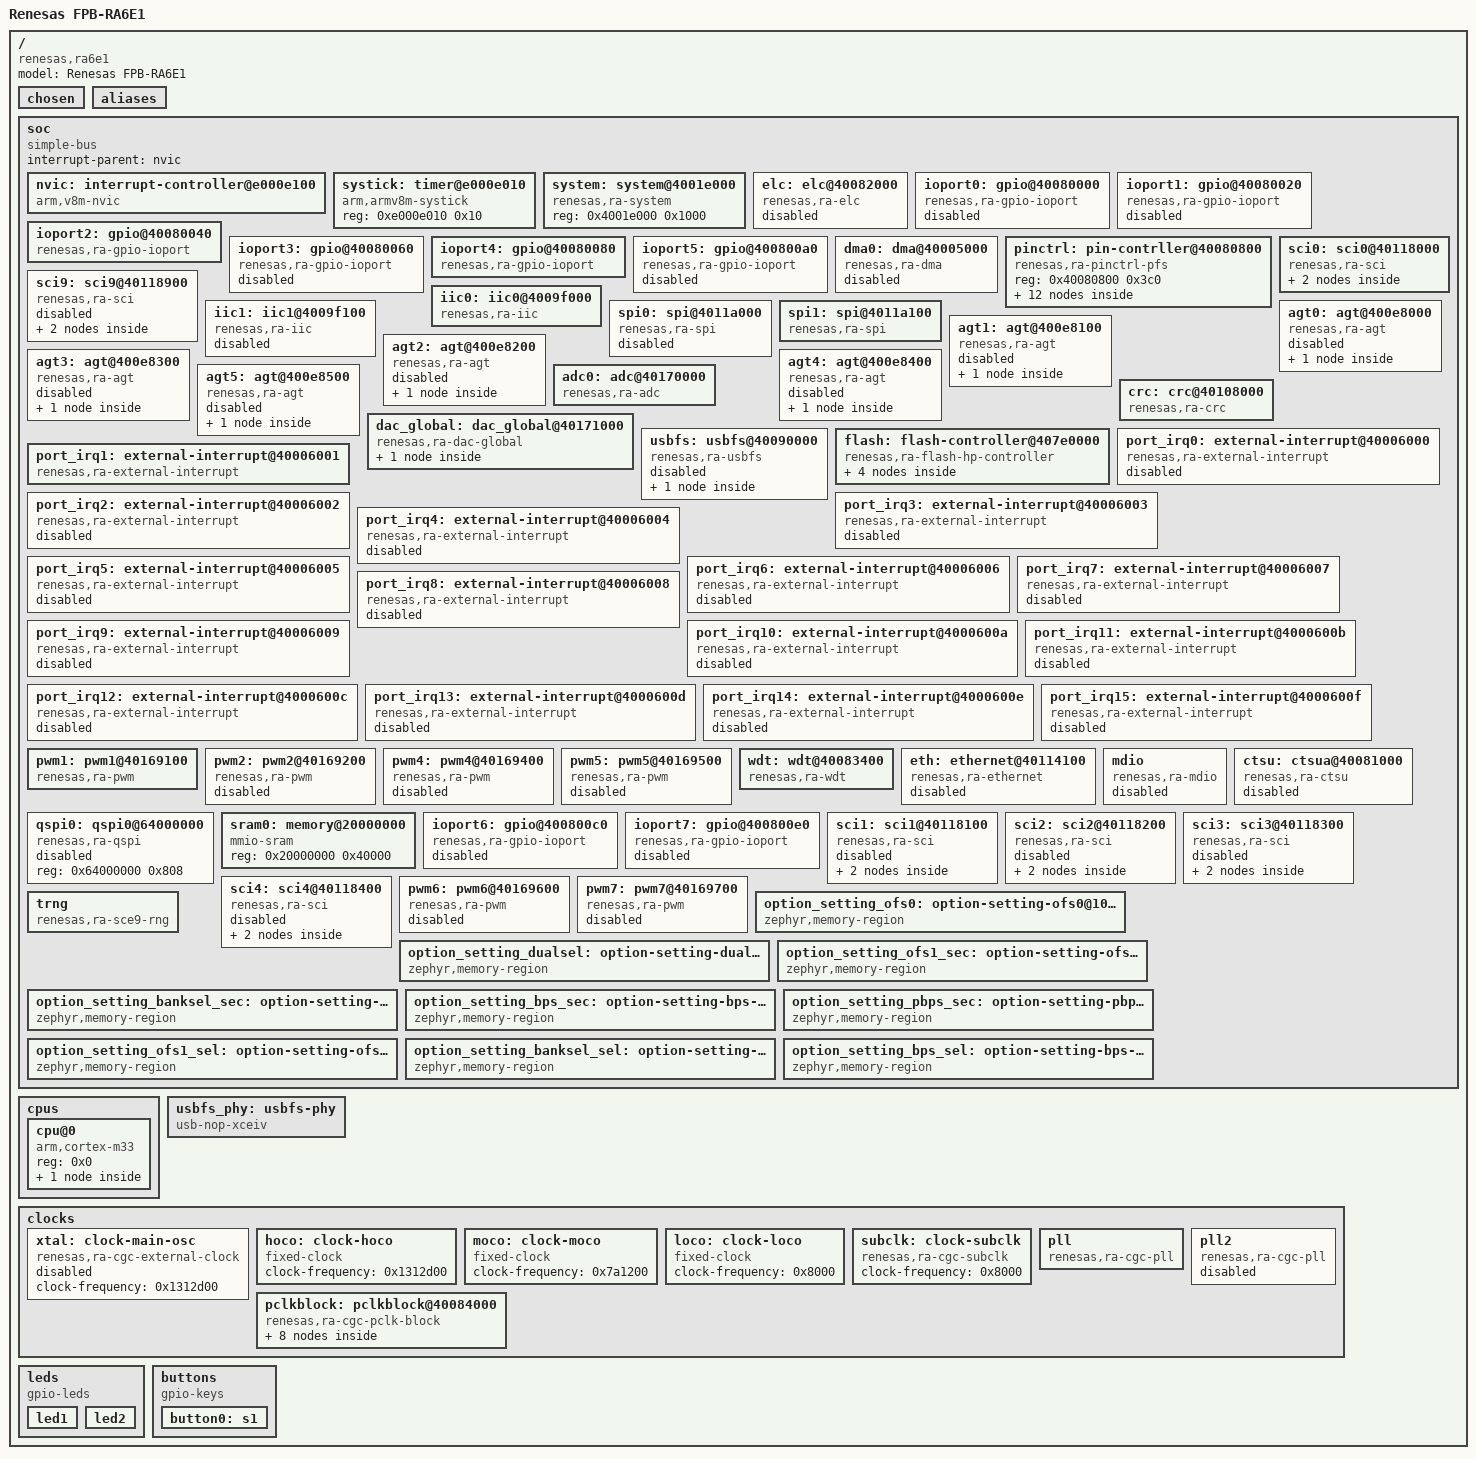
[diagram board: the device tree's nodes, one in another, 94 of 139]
/dts-v1/;

/* node '/' defined in zephyr/dts/common/skeleton.dtsi:9 */
/ {
	#address-cells = < 0x1 >;     /* in zephyr/dts/common/skeleton.dtsi:10 */
	#size-cells = < 0x1 >;        /* in zephyr/dts/common/skeleton.dtsi:11 */
	model = "Renesas FPB-RA6E1";  /* in zephyr/boards/renesas/fpb_ra6e1/fpb_ra6e1.dts:16 */
	compatible = "renesas,ra6e1",
	             "renesas,ra";    /* in zephyr/boards/renesas/fpb_ra6e1/fpb_ra6e1.dts:17 */

	/* node '/chosen' defined in zephyr/dts/common/skeleton.dtsi:13 */
	chosen {
		zephyr,sram = &sram0;              /* in zephyr/boards/renesas/fpb_ra6e1/fpb_ra6e1.dts:20 */
		zephyr,flash-controller = &flash1; /* in zephyr/boards/renesas/fpb_ra6e1/fpb_ra6e1.dts:21 */
		zephyr,flash = &flash0;            /* in zephyr/boards/renesas/fpb_ra6e1/fpb_ra6e1.dts:22 */
		zephyr,console = &uart0;           /* in zephyr/boards/renesas/fpb_ra6e1/fpb_ra6e1.dts:23 */
		zephyr,shell-uart = &uart0;        /* in zephyr/boards/renesas/fpb_ra6e1/fpb_ra6e1.dts:24 */
		zephyr,entropy = &trng;            /* in zephyr/boards/renesas/fpb_ra6e1/fpb_ra6e1.dts:25 */
		zephyr,crc = &crc;                 /* in zephyr/boards/renesas/fpb_ra6e1/fpb_ra6e1.dts:26 */
	};

	/* node '/aliases' defined in zephyr/dts/common/skeleton.dtsi:15 */
	aliases {
		led0 = &led1;     /* in zephyr/boards/renesas/fpb_ra6e1/fpb_ra6e1.dts:54 */
		sw0 = &button0;   /* in zephyr/boards/renesas/fpb_ra6e1/fpb_ra6e1.dts:55 */
		watchdog0 = &wdt; /* in zephyr/boards/renesas/fpb_ra6e1/fpb_ra6e1.dts:56 */
	};

	/* node '/soc' defined in zephyr/dts/arm/armv8-m.dtsi:6 */
	soc {
		#address-cells = < 0x1 >;     /* in zephyr/dts/arm/armv8-m.dtsi:7 */
		#size-cells = < 0x1 >;        /* in zephyr/dts/arm/armv8-m.dtsi:8 */
		compatible = "simple-bus";    /* in zephyr/dts/arm/armv8-m.dtsi:9 */
		ranges;                       /* in zephyr/dts/arm/armv8-m.dtsi:11 */
		interrupt-parent = < &nvic >; /* in zephyr/dts/arm/renesas/ra/ra6/ra6-cm33-common.dtsi:34 */

		/* node '/soc/interrupt-controller@e000e100' defined in zephyr/dts/arm/armv8-m.dtsi:13 */
		nvic: interrupt-controller@e000e100 {
			#address-cells = < 0x1 >;            /* in zephyr/dts/arm/armv8-m.dtsi:14 */
			compatible = "arm,v8m-nvic";         /* in zephyr/dts/arm/armv8-m.dtsi:15 */
			reg = < 0xe000e100 0xc00 >;          /* in zephyr/dts/arm/armv8-m.dtsi:16 */
			interrupt-controller;                /* in zephyr/dts/arm/armv8-m.dtsi:17 */
			#interrupt-cells = < 0x2 >;          /* in zephyr/dts/arm/armv8-m.dtsi:18 */
			arm,num-irq-priority-bits = < 0x4 >; /* in zephyr/dts/arm/renesas/ra/ra6/ra6-cm33-common.dtsi:603 */
			phandle = < 0x1 >;                   /* in zephyr/dts/arm/renesas/ra/ra6/ra6-cm33-common.dtsi:34 */
		};

		/* node '/soc/timer@e000e010' defined in zephyr/dts/arm/armv8-m.dtsi:21 */
		systick: timer@e000e010 {
			compatible = "arm,armv8m-systick"; /* in zephyr/dts/arm/armv8-m.dtsi:22 */
			reg = < 0xe000e010 0x10 >;         /* in zephyr/dts/arm/armv8-m.dtsi:23 */
		};

		/* node '/soc/system@4001e000' defined in zephyr/dts/arm/renesas/ra/ra6/ra6-cm33-common.dtsi:36 */
		system: system@4001e000 {
			compatible = "renesas,ra-system"; /* in zephyr/dts/arm/renesas/ra/ra6/ra6-cm33-common.dtsi:37 */
			reg = < 0x4001e000 0x1000 >;      /* in zephyr/dts/arm/renesas/ra/ra6/ra6-cm33-common.dtsi:38 */
			status = "okay";                  /* in zephyr/dts/arm/renesas/ra/ra6/ra6-cm33-common.dtsi:39 */
		};

		/* node '/soc/elc@40082000' defined in zephyr/dts/arm/renesas/ra/ra6/ra6-cm33-common.dtsi:42 */
		elc: elc@40082000 {
			compatible = "renesas,ra-elc"; /* in zephyr/dts/arm/renesas/ra/ra6/ra6-cm33-common.dtsi:43 */
			reg = < 0x40082000 0x70 >;     /* in zephyr/dts/arm/renesas/ra/ra6/ra6-cm33-common.dtsi:44 */
			#renesas-elc-cells = < 0x2 >;  /* in zephyr/dts/arm/renesas/ra/ra6/ra6-cm33-common.dtsi:45 */
			clocks = < &pclkb 0x2 0xe >;   /* in zephyr/dts/arm/renesas/ra/ra6/ra6-cm33-common.dtsi:46 */
			status = "disabled";           /* in zephyr/dts/arm/renesas/ra/ra6/ra6-cm33-common.dtsi:47 */
		};

		/* node '/soc/gpio@40080000' defined in zephyr/dts/arm/renesas/ra/ra6/ra6-cm33-common.dtsi:50 */
		ioport0: gpio@40080000 {
			compatible = "renesas,ra-gpio-ioport";                                                                       /* in zephyr/dts/arm/renesas/ra/ra6/ra6-cm33-common.dtsi:51 */
			reg = < 0x40080000 0x20 >;                                                                                   /* in zephyr/dts/arm/renesas/ra/ra6/ra6-cm33-common.dtsi:52 */
			port = < 0x0 >;                                                                                              /* in zephyr/dts/arm/renesas/ra/ra6/ra6-cm33-common.dtsi:53 */
			gpio-controller;                                                                                             /* in zephyr/dts/arm/renesas/ra/ra6/ra6-cm33-common.dtsi:54 */
			#gpio-cells = < 0x2 >;                                                                                       /* in zephyr/dts/arm/renesas/ra/ra6/ra6-cm33-common.dtsi:55 */
			ngpios = < 0x10 >;                                                                                           /* in zephyr/dts/arm/renesas/ra/ra6/ra6-cm33-common.dtsi:56 */
			status = "disabled";                                                                                         /* in zephyr/dts/arm/renesas/ra/ra6/ra6-cm33-common.dtsi:57 */
			port-irqs = < &port_irq6 &port_irq7 &port_irq8 &port_irq9 &port_irq10 &port_irq11 &port_irq12 &port_irq13 >; /* in zephyr/dts/arm/renesas/ra/ra6/r7fa6e10x.dtsi:353 */
			port-irq-names = "port-irq6",
			                 "port-irq7",
			                 "port-irq8",
			                 "port-irq9",
			                 "port-irq10",
			                 "port-irq11",
			                 "port-irq12",
			                 "port-irq13";                                                                               /* in zephyr/dts/arm/renesas/ra/ra6/r7fa6e10x.dtsi:356 */
			port-irq6-pins = < 0x0 >;                                                                                    /* in zephyr/dts/arm/renesas/ra/ra6/r7fa6e10x.dtsi:364 */
			port-irq7-pins = < 0x1 >;                                                                                    /* in zephyr/dts/arm/renesas/ra/ra6/r7fa6e10x.dtsi:365 */
			port-irq8-pins = < 0x2 >;                                                                                    /* in zephyr/dts/arm/renesas/ra/ra6/r7fa6e10x.dtsi:366 */
			port-irq9-pins = < 0x4 >;                                                                                    /* in zephyr/dts/arm/renesas/ra/ra6/r7fa6e10x.dtsi:367 */
			port-irq10-pins = < 0x5 >;                                                                                   /* in zephyr/dts/arm/renesas/ra/ra6/r7fa6e10x.dtsi:368 */
			port-irq11-pins = < 0x6 >;                                                                                   /* in zephyr/dts/arm/renesas/ra/ra6/r7fa6e10x.dtsi:369 */
			port-irq12-pins = < 0x8 >;                                                                                   /* in zephyr/dts/arm/renesas/ra/ra6/r7fa6e10x.dtsi:370 */
			port-irq13-pins = < 0xf >;                                                                                   /* in zephyr/dts/arm/renesas/ra/ra6/r7fa6e10x.dtsi:371 */
		};

		/* node '/soc/gpio@40080020' defined in zephyr/dts/arm/renesas/ra/ra6/ra6-cm33-common.dtsi:60 */
		ioport1: gpio@40080020 {
			compatible = "renesas,ra-gpio-ioport";                                  /* in zephyr/dts/arm/renesas/ra/ra6/ra6-cm33-common.dtsi:61 */
			reg = < 0x40080020 0x20 >;                                              /* in zephyr/dts/arm/renesas/ra/ra6/ra6-cm33-common.dtsi:62 */
			port = < 0x1 >;                                                         /* in zephyr/dts/arm/renesas/ra/ra6/ra6-cm33-common.dtsi:63 */
			gpio-controller;                                                        /* in zephyr/dts/arm/renesas/ra/ra6/ra6-cm33-common.dtsi:64 */
			#gpio-cells = < 0x2 >;                                                  /* in zephyr/dts/arm/renesas/ra/ra6/ra6-cm33-common.dtsi:65 */
			ngpios = < 0x10 >;                                                      /* in zephyr/dts/arm/renesas/ra/ra6/ra6-cm33-common.dtsi:66 */
			status = "disabled";                                                    /* in zephyr/dts/arm/renesas/ra/ra6/ra6-cm33-common.dtsi:67 */
			port-irqs = < &port_irq0 &port_irq1 &port_irq2 &port_irq3 &port_irq4 >; /* in zephyr/dts/arm/renesas/ra/ra6/r7fa6e10x.dtsi:375 */
			port-irq-names = "port-irq0",
			                 "port-irq1",
			                 "port-irq2",
			                 "port-irq3",
			                 "port-irq4";                                           /* in zephyr/dts/arm/renesas/ra/ra6/r7fa6e10x.dtsi:377 */
			port-irq0-pins = < 0x5 >;                                               /* in zephyr/dts/arm/renesas/ra/ra6/r7fa6e10x.dtsi:382 */
			port-irq1-pins = < 0x1 0x4 >;                                           /* in zephyr/dts/arm/renesas/ra/ra6/r7fa6e10x.dtsi:383 */
			port-irq2-pins = < 0x0 >;                                               /* in zephyr/dts/arm/renesas/ra/ra6/r7fa6e10x.dtsi:384 */
			port-irq3-pins = < 0xa >;                                               /* in zephyr/dts/arm/renesas/ra/ra6/r7fa6e10x.dtsi:385 */
			port-irq4-pins = < 0xb >;                                               /* in zephyr/dts/arm/renesas/ra/ra6/r7fa6e10x.dtsi:386 */
		};

		/* node '/soc/gpio@40080040' defined in zephyr/dts/arm/renesas/ra/ra6/ra6-cm33-common.dtsi:70 */
		ioport2: gpio@40080040 {
			compatible = "renesas,ra-gpio-ioport";                       /* in zephyr/dts/arm/renesas/ra/ra6/ra6-cm33-common.dtsi:71 */
			reg = < 0x40080040 0x20 >;                                   /* in zephyr/dts/arm/renesas/ra/ra6/ra6-cm33-common.dtsi:72 */
			port = < 0x2 >;                                              /* in zephyr/dts/arm/renesas/ra/ra6/ra6-cm33-common.dtsi:73 */
			gpio-controller;                                             /* in zephyr/dts/arm/renesas/ra/ra6/ra6-cm33-common.dtsi:74 */
			#gpio-cells = < 0x2 >;                                       /* in zephyr/dts/arm/renesas/ra/ra6/ra6-cm33-common.dtsi:75 */
			ngpios = < 0x10 >;                                           /* in zephyr/dts/arm/renesas/ra/ra6/ra6-cm33-common.dtsi:76 */
			port-irqs = < &port_irq0 &port_irq1 &port_irq2 &port_irq3 >; /* in zephyr/dts/arm/renesas/ra/ra6/r7fa6e10x.dtsi:390 */
			port-irq-names = "port-irq0",
			                 "port-irq1",
			                 "port-irq2",
			                 "port-irq3";                                /* in zephyr/dts/arm/renesas/ra/ra6/r7fa6e10x.dtsi:392 */
			port-irq0-pins = < 0x6 >;                                    /* in zephyr/dts/arm/renesas/ra/ra6/r7fa6e10x.dtsi:396 */
			port-irq1-pins = < 0x5 >;                                    /* in zephyr/dts/arm/renesas/ra/ra6/r7fa6e10x.dtsi:397 */
			port-irq2-pins = < 0xd >;                                    /* in zephyr/dts/arm/renesas/ra/ra6/r7fa6e10x.dtsi:398 */
			port-irq3-pins = < 0xc >;                                    /* in zephyr/dts/arm/renesas/ra/ra6/r7fa6e10x.dtsi:399 */
			status = "okay";                                             /* in zephyr/boards/renesas/fpb_ra6e1/fpb_ra6e1.dts:89 */
			phandle = < 0x22 >;                                          /* in zephyr/boards/renesas/fpb_ra6e1/fpb_ra6e1.dts:47 */
		};

		/* node '/soc/gpio@40080060' defined in zephyr/dts/arm/renesas/ra/ra6/ra6-cm33-common.dtsi:80 */
		ioport3: gpio@40080060 {
			compatible = "renesas,ra-gpio-ioport";                       /* in zephyr/dts/arm/renesas/ra/ra6/ra6-cm33-common.dtsi:81 */
			reg = < 0x40080060 0x20 >;                                   /* in zephyr/dts/arm/renesas/ra/ra6/ra6-cm33-common.dtsi:82 */
			port = < 0x3 >;                                              /* in zephyr/dts/arm/renesas/ra/ra6/ra6-cm33-common.dtsi:83 */
			gpio-controller;                                             /* in zephyr/dts/arm/renesas/ra/ra6/ra6-cm33-common.dtsi:84 */
			#gpio-cells = < 0x2 >;                                       /* in zephyr/dts/arm/renesas/ra/ra6/ra6-cm33-common.dtsi:85 */
			ngpios = < 0x10 >;                                           /* in zephyr/dts/arm/renesas/ra/ra6/ra6-cm33-common.dtsi:86 */
			status = "disabled";                                         /* in zephyr/dts/arm/renesas/ra/ra6/ra6-cm33-common.dtsi:87 */
			port-irqs = < &port_irq5 &port_irq6 &port_irq8 &port_irq9 >; /* in zephyr/dts/arm/renesas/ra/ra6/r7fa6e10x.dtsi:403 */
			port-irq-names = "port-irq5",
			                 "port-irq6",
			                 "port-irq8",
			                 "port-irq9";                                /* in zephyr/dts/arm/renesas/ra/ra6/r7fa6e10x.dtsi:405 */
			port-irq5-pins = < 0x2 >;                                    /* in zephyr/dts/arm/renesas/ra/ra6/r7fa6e10x.dtsi:409 */
			port-irq6-pins = < 0x1 >;                                    /* in zephyr/dts/arm/renesas/ra/ra6/r7fa6e10x.dtsi:410 */
			port-irq8-pins = < 0x5 >;                                    /* in zephyr/dts/arm/renesas/ra/ra6/r7fa6e10x.dtsi:411 */
			port-irq9-pins = < 0x4 >;                                    /* in zephyr/dts/arm/renesas/ra/ra6/r7fa6e10x.dtsi:412 */
		};

		/* node '/soc/gpio@40080080' defined in zephyr/dts/arm/renesas/ra/ra6/ra6-cm33-common.dtsi:90 */
		ioport4: gpio@40080080 {
			compatible = "renesas,ra-gpio-ioport";                                                                 /* in zephyr/dts/arm/renesas/ra/ra6/ra6-cm33-common.dtsi:91 */
			reg = < 0x40080080 0x20 >;                                                                             /* in zephyr/dts/arm/renesas/ra/ra6/ra6-cm33-common.dtsi:92 */
			port = < 0x4 >;                                                                                        /* in zephyr/dts/arm/renesas/ra/ra6/ra6-cm33-common.dtsi:93 */
			gpio-controller;                                                                                       /* in zephyr/dts/arm/renesas/ra/ra6/ra6-cm33-common.dtsi:94 */
			#gpio-cells = < 0x2 >;                                                                                 /* in zephyr/dts/arm/renesas/ra/ra6/ra6-cm33-common.dtsi:95 */
			ngpios = < 0x10 >;                                                                                     /* in zephyr/dts/arm/renesas/ra/ra6/ra6-cm33-common.dtsi:96 */
			vbatts-pins = < 0x2 0x3 0x4 >;                                                                         /* in zephyr/dts/arm/renesas/ra/ra6/ra6-cm33-common.dtsi:97 */
			port-irqs = < &port_irq0 &port_irq4 &port_irq5 &port_irq6 &port_irq7 &port_irq8 &port_irq9 &port_irq14
			              &port_irq15 >;                                                                           /* in zephyr/dts/arm/renesas/ra/ra6/r7fa6e10x.dtsi:416 */
			port-irq-names = "port-irq0",
			                 "port-irq4",
			                 "port-irq5",
			                 "port-irq6",
			                 "port-irq7",
			                 "port-irq8",
			                 "port-irq9",
			                 "port-irq14",
			                 "port-irq15";                                                                         /* in zephyr/dts/arm/renesas/ra/ra6/r7fa6e10x.dtsi:419 */
			port-irq0-pins = < 0x0 >;                                                                              /* in zephyr/dts/arm/renesas/ra/ra6/r7fa6e10x.dtsi:428 */
			port-irq4-pins = < 0x2 0xb >;                                                                          /* in zephyr/dts/arm/renesas/ra/ra6/r7fa6e10x.dtsi:429 */
			port-irq5-pins = < 0x1 0xa >;                                                                          /* in zephyr/dts/arm/renesas/ra/ra6/r7fa6e10x.dtsi:430 */
			port-irq6-pins = < 0x9 >;                                                                              /* in zephyr/dts/arm/renesas/ra/ra6/r7fa6e10x.dtsi:431 */
			port-irq7-pins = < 0x8 >;                                                                              /* in zephyr/dts/arm/renesas/ra/ra6/r7fa6e10x.dtsi:432 */
			port-irq8-pins = < 0xf >;                                                                              /* in zephyr/dts/arm/renesas/ra/ra6/r7fa6e10x.dtsi:433 */
			port-irq9-pins = < 0xe >;                                                                              /* in zephyr/dts/arm/renesas/ra/ra6/r7fa6e10x.dtsi:434 */
			port-irq14-pins = < 0x3 >;                                                                             /* in zephyr/dts/arm/renesas/ra/ra6/r7fa6e10x.dtsi:435 */
			port-irq15-pins = < 0x4 >;                                                                             /* in zephyr/dts/arm/renesas/ra/ra6/r7fa6e10x.dtsi:436 */
			status = "okay";                                                                                       /* in zephyr/boards/renesas/fpb_ra6e1/fpb_ra6e1.dts:93 */
			phandle = < 0x21 >;                                                                                    /* in zephyr/boards/renesas/fpb_ra6e1/fpb_ra6e1.dts:33 */
		};

		/* node '/soc/gpio@400800a0' defined in zephyr/dts/arm/renesas/ra/ra6/ra6-cm33-common.dtsi:101 */
		ioport5: gpio@400800a0 {
			compatible = "renesas,ra-gpio-ioport";               /* in zephyr/dts/arm/renesas/ra/ra6/ra6-cm33-common.dtsi:102 */
			reg = < 0x400800a0 0x20 >;                           /* in zephyr/dts/arm/renesas/ra/ra6/ra6-cm33-common.dtsi:103 */
			port = < 0x5 >;                                      /* in zephyr/dts/arm/renesas/ra/ra6/ra6-cm33-common.dtsi:104 */
			gpio-controller;                                     /* in zephyr/dts/arm/renesas/ra/ra6/ra6-cm33-common.dtsi:105 */
			#gpio-cells = < 0x2 >;                               /* in zephyr/dts/arm/renesas/ra/ra6/ra6-cm33-common.dtsi:106 */
			ngpios = < 0x10 >;                                   /* in zephyr/dts/arm/renesas/ra/ra6/ra6-cm33-common.dtsi:107 */
			status = "disabled";                                 /* in zephyr/dts/arm/renesas/ra/ra6/ra6-cm33-common.dtsi:108 */
			port-irqs = < &port_irq11 &port_irq12 &port_irq14 >; /* in zephyr/dts/arm/renesas/ra/ra6/r7fa6e10x.dtsi:440 */
			port-irq-names = "port-irq11",
			                 "port-irq12",
			                 "port-irq14";                       /* in zephyr/dts/arm/renesas/ra/ra6/r7fa6e10x.dtsi:441 */
			port-irq11-pins = < 0x1 >;                           /* in zephyr/dts/arm/renesas/ra/ra6/r7fa6e10x.dtsi:444 */
			port-irq12-pins = < 0x2 >;                           /* in zephyr/dts/arm/renesas/ra/ra6/r7fa6e10x.dtsi:445 */
			port-irq14-pins = < 0x5 >;                           /* in zephyr/dts/arm/renesas/ra/ra6/r7fa6e10x.dtsi:446 */
		};

		/* node '/soc/dma@40005000' defined in zephyr/dts/arm/renesas/ra/ra6/ra6-cm33-common.dtsi:111 */
		dma0: dma@40005000 {
			compatible = "renesas,ra-dma"; /* in zephyr/dts/arm/renesas/ra/ra6/ra6-cm33-common.dtsi:112 */
			reg = < 0x40005000 0x200 >,
			      < 0x40005200 0xa0 >;     /* in zephyr/dts/arm/renesas/ra/ra6/ra6-cm33-common.dtsi:113 */
			reg-names = "channel",
			            "common";          /* in zephyr/dts/arm/renesas/ra/ra6/ra6-cm33-common.dtsi:114 */
			clocks = < &iclk 0x0 0x16 >;   /* in zephyr/dts/arm/renesas/ra/ra6/ra6-cm33-common.dtsi:115 */
			dma-channels = < 0x8 >;        /* in zephyr/dts/arm/renesas/ra/ra6/ra6-cm33-common.dtsi:116 */
			#dma-cells = < 0x2 >;          /* in zephyr/dts/arm/renesas/ra/ra6/ra6-cm33-common.dtsi:117 */
			status = "disabled";           /* in zephyr/dts/arm/renesas/ra/ra6/ra6-cm33-common.dtsi:118 */
		};

		/* node '/soc/pin-contrller@40080800' defined in zephyr/dts/arm/renesas/ra/ra6/ra6-cm33-common.dtsi:121 */
		pinctrl: pin-contrller@40080800 {
			compatible = "renesas,ra-pinctrl-pfs"; /* in zephyr/dts/arm/renesas/ra/ra6/ra6-cm33-common.dtsi:122 */
			reg = < 0x40080800 0x3c0 >;            /* in zephyr/dts/arm/renesas/ra/ra6/ra6-cm33-common.dtsi:123 */
			status = "okay";                       /* in zephyr/dts/arm/renesas/ra/ra6/ra6-cm33-common.dtsi:124 */

			/* node '/soc/pin-contrller@40080800/sci0_default' defined in zephyr/boards/renesas/fpb_ra6e1/fpb_ra6e1-pinctrl.dtsi:7 */
			sci0_default: sci0_default {
				phandle = < 0x15 >; /* in zephyr/boards/renesas/fpb_ra6e1/fpb_ra6e1.dts:61 */

				/* node '/soc/pin-contrller@40080800/sci0_default/group1' defined in zephyr/boards/renesas/fpb_ra6e1/fpb_ra6e1-pinctrl.dtsi:8 */
				group1 {
					psels = < 0x2411 >,
					        < 0x2401 >; /* in zephyr/boards/renesas/fpb_ra6e1/fpb_ra6e1-pinctrl.dtsi:10 */
				};
			};

			/* node '/soc/pin-contrller@40080800/iic0_default' defined in zephyr/boards/renesas/fpb_ra6e1/fpb_ra6e1-pinctrl.dtsi:15 */
			iic0_default: iic0_default {
				phandle = < 0x16 >; /* in zephyr/boards/renesas/fpb_ra6e1/fpb_ra6e1.dts:78 */

				/* node '/soc/pin-contrller@40080800/iic0_default/group1' defined in zephyr/boards/renesas/fpb_ra6e1/fpb_ra6e1-pinctrl.dtsi:16 */
				group1 {
					psels = < 0x2704 >,
					        < 0x2714 >;        /* in zephyr/boards/renesas/fpb_ra6e1/fpb_ra6e1-pinctrl.dtsi:18 */
					drive-strength = "medium"; /* in zephyr/boards/renesas/fpb_ra6e1/fpb_ra6e1-pinctrl.dtsi:20 */
				};
			};

			/* node '/soc/pin-contrller@40080800/spi1_default' defined in zephyr/boards/renesas/fpb_ra6e1/fpb_ra6e1-pinctrl.dtsi:24 */
			spi1_default: spi1_default {
				phandle = < 0x17 >; /* in zephyr/boards/renesas/fpb_ra6e1/fpb_ra6e1.dts:83 */

				/* node '/soc/pin-contrller@40080800/spi1_default/group1' defined in zephyr/boards/renesas/fpb_ra6e1/fpb_ra6e1-pinctrl.dtsi:25 */
				group1 {
					psels = < 0x26a4 >,
					        < 0x26b4 >,
					        < 0x26c4 >,
					        < 0x26d4 >; /* in zephyr/boards/renesas/fpb_ra6e1/fpb_ra6e1-pinctrl.dtsi:27 */
				};
			};

			/* node '/soc/pin-contrller@40080800/adc0_default' defined in zephyr/boards/renesas/fpb_ra6e1/fpb_ra6e1-pinctrl.dtsi:34 */
			adc0_default: adc0_default {
				phandle = < 0x18 >; /* in zephyr/boards/renesas/fpb_ra6e1/fpb_ra6e1.dts:122 */

				/* node '/soc/pin-contrller@40080800/adc0_default/group1' defined in zephyr/boards/renesas/fpb_ra6e1/fpb_ra6e1-pinctrl.dtsi:35 */
				group1 {
					psels = < 0x2000 >;    /* in zephyr/boards/renesas/fpb_ra6e1/fpb_ra6e1-pinctrl.dtsi:37 */
					renesas,analog-enable; /* in zephyr/boards/renesas/fpb_ra6e1/fpb_ra6e1-pinctrl.dtsi:38 */
				};
			};

			/* node '/soc/pin-contrller@40080800/dac0_default' defined in zephyr/boards/renesas/fpb_ra6e1/fpb_ra6e1-pinctrl.dtsi:42 */
			dac0_default: dac0_default {
				phandle = < 0x19 >; /* in zephyr/boards/renesas/fpb_ra6e1/fpb_ra6e1.dts:127 */

				/* node '/soc/pin-contrller@40080800/dac0_default/group1' defined in zephyr/boards/renesas/fpb_ra6e1/fpb_ra6e1-pinctrl.dtsi:43 */
				group1 {
					psels = < 0x20e0 >;    /* in zephyr/boards/renesas/fpb_ra6e1/fpb_ra6e1-pinctrl.dtsi:45 */
					renesas,analog-enable; /* in zephyr/boards/renesas/fpb_ra6e1/fpb_ra6e1-pinctrl.dtsi:46 */
				};
			};

			/* node '/soc/pin-contrller@40080800/pwm1_default' defined in zephyr/boards/renesas/fpb_ra6e1/fpb_ra6e1-pinctrl.dtsi:50 */
			pwm1_default: pwm1_default {
				phandle = < 0x1e >; /* in zephyr/boards/renesas/fpb_ra6e1/fpb_ra6e1.dts:138 */

				/* node '/soc/pin-contrller@40080800/pwm1_default/group1' defined in zephyr/boards/renesas/fpb_ra6e1/fpb_ra6e1-pinctrl.dtsi:51 */
				group1 {
					psels = < 0x2354 >,
					        < 0x2364 >; /* in zephyr/boards/renesas/fpb_ra6e1/fpb_ra6e1-pinctrl.dtsi:53 */
				};
			};
		};

		/* node '/soc/sci0@40118000' defined in zephyr/dts/arm/renesas/ra/ra6/ra6-cm33-common.dtsi:127 */
		sci0: sci0@40118000 {
			compatible = "renesas,ra-sci"; /* in zephyr/dts/arm/renesas/ra/ra6/ra6-cm33-common.dtsi:128 */
			interrupts = < 0x0 0x1 >,
			             < 0x1 0x1 >,
			             < 0x2 0x1 >,
			             < 0x3 0x1 >;      /* in zephyr/dts/arm/renesas/ra/ra6/ra6-cm33-common.dtsi:129 */
			interrupt-names = "rxi",
			                  "txi",
			                  "tei",
			                  "eri";       /* in zephyr/dts/arm/renesas/ra/ra6/ra6-cm33-common.dtsi:130 */
			reg = < 0x40118000 0x100 >;    /* in zephyr/dts/arm/renesas/ra/ra6/ra6-cm33-common.dtsi:131 */
			clocks = < &pclka 0x1 0x1f >;  /* in zephyr/dts/arm/renesas/ra/ra6/ra6-cm33-common.dtsi:132 */
			pinctrl-0 = < &sci0_default >; /* in zephyr/boards/renesas/fpb_ra6e1/fpb_ra6e1.dts:61 */
			pinctrl-names = "default";     /* in zephyr/boards/renesas/fpb_ra6e1/fpb_ra6e1.dts:62 */
			status = "okay";               /* in zephyr/boards/renesas/fpb_ra6e1/fpb_ra6e1.dts:63 */

			/* node '/soc/sci0@40118000/uart' defined in zephyr/dts/arm/renesas/ra/ra6/ra6-cm33-common.dtsi:135 */
			uart0: uart {
				compatible = "renesas,ra-sci-uart"; /* in zephyr/dts/arm/renesas/ra/ra6/ra6-cm33-common.dtsi:136 */
				channel = < 0x0 >;                  /* in zephyr/dts/arm/renesas/ra/ra6/ra6-cm33-common.dtsi:137 */
				current-speed = < 0x1c200 >;        /* in zephyr/boards/renesas/fpb_ra6e1/fpb_ra6e1.dts:66 */
				status = "okay";                    /* in zephyr/boards/renesas/fpb_ra6e1/fpb_ra6e1.dts:67 */
			};

			/* node '/soc/sci0@40118000/i2c' defined in zephyr/dts/arm/renesas/ra/ra6/ra6-cm33-common.dtsi:141 */
			i2c {
				compatible = "renesas,ra-sci-i2c"; /* in zephyr/dts/arm/renesas/ra/ra6/ra6-cm33-common.dtsi:142 */
				#address-cells = < 0x1 >;          /* in zephyr/dts/arm/renesas/ra/ra6/ra6-cm33-common.dtsi:143 */
				#size-cells = < 0x0 >;             /* in zephyr/dts/arm/renesas/ra/ra6/ra6-cm33-common.dtsi:144 */
				channel = < 0x0 >;                 /* in zephyr/dts/arm/renesas/ra/ra6/ra6-cm33-common.dtsi:145 */
				status = "disabled";               /* in zephyr/dts/arm/renesas/ra/ra6/ra6-cm33-common.dtsi:146 */
			};
		};

		/* node '/soc/sci9@40118900' defined in zephyr/dts/arm/renesas/ra/ra6/ra6-cm33-common.dtsi:150 */
		sci9: sci9@40118900 {
			compatible = "renesas,ra-sci"; /* in zephyr/dts/arm/renesas/ra/ra6/ra6-cm33-common.dtsi:151 */
			interrupts = < 0x4a 0x1 >,
			             < 0x4b 0x1 >,
			             < 0x4c 0x1 >,
			             < 0x4d 0x1 >;     /* in zephyr/dts/arm/renesas/ra/ra6/ra6-cm33-common.dtsi:152 */
			interrupt-names = "rxi",
			                  "txi",
			                  "tei",
			                  "eri";       /* in zephyr/dts/arm/renesas/ra/ra6/ra6-cm33-common.dtsi:153 */
			reg = < 0x40118900 0x100 >;    /* in zephyr/dts/arm/renesas/ra/ra6/ra6-cm33-common.dtsi:154 */
			clocks = < &pclka 0x1 0x16 >;  /* in zephyr/dts/arm/renesas/ra/ra6/ra6-cm33-common.dtsi:155 */
			status = "disabled";           /* in zephyr/dts/arm/renesas/ra/ra6/ra6-cm33-common.dtsi:156 */

			/* node '/soc/sci9@40118900/uart' defined in zephyr/dts/arm/renesas/ra/ra6/ra6-cm33-common.dtsi:158 */
			uart {
				compatible = "renesas,ra-sci-uart"; /* in zephyr/dts/arm/renesas/ra/ra6/ra6-cm33-common.dtsi:159 */
				channel = < 0x9 >;                  /* in zephyr/dts/arm/renesas/ra/ra6/ra6-cm33-common.dtsi:160 */
				status = "disabled";                /* in zephyr/dts/arm/renesas/ra/ra6/ra6-cm33-common.dtsi:161 */
			};

			/* node '/soc/sci9@40118900/i2c' defined in zephyr/dts/arm/renesas/ra/ra6/ra6-cm33-common.dtsi:164 */
			i2c {
				compatible = "renesas,ra-sci-i2c"; /* in zephyr/dts/arm/renesas/ra/ra6/ra6-cm33-common.dtsi:165 */
				#address-cells = < 0x1 >;          /* in zephyr/dts/arm/renesas/ra/ra6/ra6-cm33-common.dtsi:166 */
				#size-cells = < 0x0 >;             /* in zephyr/dts/arm/renesas/ra/ra6/ra6-cm33-common.dtsi:167 */
				channel = < 0x9 >;                 /* in zephyr/dts/arm/renesas/ra/ra6/ra6-cm33-common.dtsi:168 */
				status = "disabled";               /* in zephyr/dts/arm/renesas/ra/ra6/ra6-cm33-common.dtsi:169 */
			};
		};

		/* node '/soc/iic0@4009f000' defined in zephyr/dts/arm/renesas/ra/ra6/ra6-cm33-common.dtsi:173 */
		iic0: iic0@4009f000 {
			compatible = "renesas,ra-iic"; /* in zephyr/dts/arm/renesas/ra/ra6/ra6-cm33-common.dtsi:174 */
			channel = < 0x0 >;             /* in zephyr/dts/arm/renesas/ra/ra6/ra6-cm33-common.dtsi:175 */
			reg = < 0x4009f000 0x100 >;    /* in zephyr/dts/arm/renesas/ra/ra6/ra6-cm33-common.dtsi:176 */
			status = "okay";               /* in zephyr/boards/renesas/fpb_ra6e1/fpb_ra6e1.dts:72 */
			#address-cells = < 0x1 >;      /* in zephyr/boards/renesas/fpb_ra6e1/fpb_ra6e1.dts:73 */
			#size-cells = < 0x0 >;         /* in zephyr/boards/renesas/fpb_ra6e1/fpb_ra6e1.dts:74 */
			interrupts = < 0x5b 0x1 >,
			             < 0x5c 0x1 >,
			             < 0x5d 0x1 >,
			             < 0x5e 0x1 >;     /* in zephyr/boards/renesas/fpb_ra6e1/fpb_ra6e1.dts:75 */
			interrupt-names = "rxi",
			                  "txi",
			                  "tei",
			                  "eri";       /* in zephyr/boards/renesas/fpb_ra6e1/fpb_ra6e1.dts:76 */
			clock-frequency = < 0xf4240 >; /* in zephyr/boards/renesas/fpb_ra6e1/fpb_ra6e1.dts:77 */
			pinctrl-0 = < &iic0_default >; /* in zephyr/boards/renesas/fpb_ra6e1/fpb_ra6e1.dts:78 */
			pinctrl-names = "default";     /* in zephyr/boards/renesas/fpb_ra6e1/fpb_ra6e1.dts:79 */
		};

		/* node '/soc/iic1@4009f100' defined in zephyr/dts/arm/renesas/ra/ra6/ra6-cm33-common.dtsi:180 */
		iic1: iic1@4009f100 {
			compatible = "renesas,ra-iic"; /* in zephyr/dts/arm/renesas/ra/ra6/ra6-cm33-common.dtsi:181 */
			channel = < 0x1 >;             /* in zephyr/dts/arm/renesas/ra/ra6/ra6-cm33-common.dtsi:182 */
			reg = < 0x4009f100 0x100 >;    /* in zephyr/dts/arm/renesas/ra/ra6/ra6-cm33-common.dtsi:183 */
			status = "disabled";           /* in zephyr/dts/arm/renesas/ra/ra6/ra6-cm33-common.dtsi:184 */
		};

		/* node '/soc/spi@4011a000' defined in zephyr/dts/arm/renesas/ra/ra6/ra6-cm33-common.dtsi:187 */
		spi0: spi@4011a000 {
			compatible = "renesas,ra-spi"; /* in zephyr/dts/arm/renesas/ra/ra6/ra6-cm33-common.dtsi:188 */
			#address-cells = < 0x1 >;      /* in zephyr/dts/arm/renesas/ra/ra6/ra6-cm33-common.dtsi:189 */
			#size-cells = < 0x0 >;         /* in zephyr/dts/arm/renesas/ra/ra6/ra6-cm33-common.dtsi:190 */
			channel = < 0x0 >;             /* in zephyr/dts/arm/renesas/ra/ra6/ra6-cm33-common.dtsi:191 */
			interrupts = < 0x4e 0x1 >,
			             < 0x4f 0x1 >,
			             < 0x50 0x1 >,
			             < 0x51 0x1 >;     /* in zephyr/dts/arm/renesas/ra/ra6/ra6-cm33-common.dtsi:192 */
			interrupt-names = "rxi",
			                  "txi",
			                  "tei",
			                  "eri";       /* in zephyr/dts/arm/renesas/ra/ra6/ra6-cm33-common.dtsi:193 */
			reg = < 0x4011a000 0x100 >;    /* in zephyr/dts/arm/renesas/ra/ra6/ra6-cm33-common.dtsi:194 */
			status = "disabled";           /* in zephyr/dts/arm/renesas/ra/ra6/ra6-cm33-common.dtsi:195 */
		};

		/* node '/soc/spi@4011a100' defined in zephyr/dts/arm/renesas/ra/ra6/ra6-cm33-common.dtsi:198 */
		spi1: spi@4011a100 {
			compatible = "renesas,ra-spi"; /* in zephyr/dts/arm/renesas/ra/ra6/ra6-cm33-common.dtsi:199 */
			#address-cells = < 0x1 >;      /* in zephyr/dts/arm/renesas/ra/ra6/ra6-cm33-common.dtsi:200 */
			#size-cells = < 0x0 >;         /* in zephyr/dts/arm/renesas/ra/ra6/ra6-cm33-common.dtsi:201 */
			channel = < 0x1 >;             /* in zephyr/dts/arm/renesas/ra/ra6/ra6-cm33-common.dtsi:202 */
			interrupts = < 0x52 0x1 >,
			             < 0x53 0x1 >,
			             < 0x54 0x1 >,
			             < 0x55 0x1 >;     /* in zephyr/dts/arm/renesas/ra/ra6/ra6-cm33-common.dtsi:203 */
			interrupt-names = "rxi",
			                  "txi",
			                  "tei",
			                  "eri";       /* in zephyr/dts/arm/renesas/ra/ra6/ra6-cm33-common.dtsi:204 */
			reg = < 0x4011a100 0x100 >;    /* in zephyr/dts/arm/renesas/ra/ra6/ra6-cm33-common.dtsi:205 */
			pinctrl-0 = < &spi1_default >; /* in zephyr/boards/renesas/fpb_ra6e1/fpb_ra6e1.dts:83 */
			pinctrl-names = "default";     /* in zephyr/boards/renesas/fpb_ra6e1/fpb_ra6e1.dts:84 */
			status = "okay";               /* in zephyr/boards/renesas/fpb_ra6e1/fpb_ra6e1.dts:85 */
		};

		/* node '/soc/agt@400e8000' defined in zephyr/dts/arm/renesas/ra/ra6/ra6-cm33-common.dtsi:209 */
		agt0: agt@400e8000 {
			compatible = "renesas,ra-agt";           /* in zephyr/dts/arm/renesas/ra/ra6/ra6-cm33-common.dtsi:210 */
			channel = < 0x0 >;                       /* in zephyr/dts/arm/renesas/ra/ra6/ra6-cm33-common.dtsi:211 */
			reg = < 0x400e8000 0x100 >;              /* in zephyr/dts/arm/renesas/ra/ra6/ra6-cm33-common.dtsi:212 */
			renesas,count-source = "AGT_CLOCK_LOCO"; /* in zephyr/dts/arm/renesas/ra/ra6/ra6-cm33-common.dtsi:213 */
			renesas,prescaler = < 0x0 >;             /* in zephyr/dts/arm/renesas/ra/ra6/ra6-cm33-common.dtsi:214 */
			renesas,resolution = < 0x10 >;           /* in zephyr/dts/arm/renesas/ra/ra6/ra6-cm33-common.dtsi:215 */
			status = "disabled";                     /* in zephyr/dts/arm/renesas/ra/ra6/ra6-cm33-common.dtsi:216 */

			/* node '/soc/agt@400e8000/counter' defined in zephyr/dts/arm/renesas/ra/ra6/ra6-cm33-common.dtsi:218 */
			counter {
				compatible = "renesas,ra-agt-counter"; /* in zephyr/dts/arm/renesas/ra/ra6/ra6-cm33-common.dtsi:219 */
				status = "disabled";                   /* in zephyr/dts/arm/renesas/ra/ra6/ra6-cm33-common.dtsi:220 */
			};
		};

		/* node '/soc/agt@400e8100' defined in zephyr/dts/arm/renesas/ra/ra6/ra6-cm33-common.dtsi:224 */
		agt1: agt@400e8100 {
			compatible = "renesas,ra-agt";           /* in zephyr/dts/arm/renesas/ra/ra6/ra6-cm33-common.dtsi:225 */
			channel = < 0x1 >;                       /* in zephyr/dts/arm/renesas/ra/ra6/ra6-cm33-common.dtsi:226 */
			reg = < 0x400e8100 0x100 >;              /* in zephyr/dts/arm/renesas/ra/ra6/ra6-cm33-common.dtsi:227 */
			renesas,count-source = "AGT_CLOCK_LOCO"; /* in zephyr/dts/arm/renesas/ra/ra6/ra6-cm33-common.dtsi:228 */
			renesas,prescaler = < 0x0 >;             /* in zephyr/dts/arm/renesas/ra/ra6/ra6-cm33-common.dtsi:229 */
			renesas,resolution = < 0x10 >;           /* in zephyr/dts/arm/renesas/ra/ra6/ra6-cm33-common.dtsi:230 */
			status = "disabled";                     /* in zephyr/dts/arm/renesas/ra/ra6/ra6-cm33-common.dtsi:231 */

			/* node '/soc/agt@400e8100/counter' defined in zephyr/dts/arm/renesas/ra/ra6/ra6-cm33-common.dtsi:233 */
			counter {
				compatible = "renesas,ra-agt-counter"; /* in zephyr/dts/arm/renesas/ra/ra6/ra6-cm33-common.dtsi:234 */
				status = "disabled";                   /* in zephyr/dts/arm/renesas/ra/ra6/ra6-cm33-common.dtsi:235 */
			};
		};

		/* node '/soc/agt@400e8200' defined in zephyr/dts/arm/renesas/ra/ra6/ra6-cm33-common.dtsi:239 */
		agt2: agt@400e8200 {
			compatible = "renesas,ra-agt";           /* in zephyr/dts/arm/renesas/ra/ra6/ra6-cm33-common.dtsi:240 */
			channel = < 0x2 >;                       /* in zephyr/dts/arm/renesas/ra/ra6/ra6-cm33-common.dtsi:241 */
			reg = < 0x400e8200 0x100 >;              /* in zephyr/dts/arm/renesas/ra/ra6/ra6-cm33-common.dtsi:242 */
			renesas,count-source = "AGT_CLOCK_LOCO"; /* in zephyr/dts/arm/renesas/ra/ra6/ra6-cm33-common.dtsi:243 */
			renesas,prescaler = < 0x0 >;             /* in zephyr/dts/arm/renesas/ra/ra6/ra6-cm33-common.dtsi:244 */
			renesas,resolution = < 0x10 >;           /* in zephyr/dts/arm/renesas/ra/ra6/ra6-cm33-common.dtsi:245 */
			status = "disabled";                     /* in zephyr/dts/arm/renesas/ra/ra6/ra6-cm33-common.dtsi:246 */

			/* node '/soc/agt@400e8200/counter' defined in zephyr/dts/arm/renesas/ra/ra6/ra6-cm33-common.dtsi:248 */
			counter {
				compatible = "renesas,ra-agt-counter"; /* in zephyr/dts/arm/renesas/ra/ra6/ra6-cm33-common.dtsi:249 */
				status = "disabled";                   /* in zephyr/dts/arm/renesas/ra/ra6/ra6-cm33-common.dtsi:250 */
			};
		};

		/* node '/soc/agt@400e8300' defined in zephyr/dts/arm/renesas/ra/ra6/ra6-cm33-common.dtsi:254 */
		agt3: agt@400e8300 {
			compatible = "renesas,ra-agt";           /* in zephyr/dts/arm/renesas/ra/ra6/ra6-cm33-common.dtsi:255 */
			channel = < 0x3 >;                       /* in zephyr/dts/arm/renesas/ra/ra6/ra6-cm33-common.dtsi:256 */
			reg = < 0x400e8300 0x100 >;              /* in zephyr/dts/arm/renesas/ra/ra6/ra6-cm33-common.dtsi:257 */
			renesas,count-source = "AGT_CLOCK_LOCO"; /* in zephyr/dts/arm/renesas/ra/ra6/ra6-cm33-common.dtsi:258 */
			renesas,prescaler = < 0x0 >;             /* in zephyr/dts/arm/renesas/ra/ra6/ra6-cm33-common.dtsi:259 */
			renesas,resolution = < 0x10 >;           /* in zephyr/dts/arm/renesas/ra/ra6/ra6-cm33-common.dtsi:260 */
			status = "disabled";                     /* in zephyr/dts/arm/renesas/ra/ra6/ra6-cm33-common.dtsi:261 */

			/* node '/soc/agt@400e8300/counter' defined in zephyr/dts/arm/renesas/ra/ra6/ra6-cm33-common.dtsi:263 */
			counter {
				compatible = "renesas,ra-agt-counter"; /* in zephyr/dts/arm/renesas/ra/ra6/ra6-cm33-common.dtsi:264 */
				status = "disabled";                   /* in zephyr/dts/arm/renesas/ra/ra6/ra6-cm33-common.dtsi:265 */
			};
		};

		/* node '/soc/agt@400e8400' defined in zephyr/dts/arm/renesas/ra/ra6/ra6-cm33-common.dtsi:269 */
		agt4: agt@400e8400 {
			compatible = "renesas,ra-agt";           /* in zephyr/dts/arm/renesas/ra/ra6/ra6-cm33-common.dtsi:270 */
			channel = < 0x4 >;                       /* in zephyr/dts/arm/renesas/ra/ra6/ra6-cm33-common.dtsi:271 */
			reg = < 0x400e8400 0x100 >;              /* in zephyr/dts/arm/renesas/ra/ra6/ra6-cm33-common.dtsi:272 */
			renesas,count-source = "AGT_CLOCK_LOCO"; /* in zephyr/dts/arm/renesas/ra/ra6/ra6-cm33-common.dtsi:273 */
			renesas,prescaler = < 0x0 >;             /* in zephyr/dts/arm/renesas/ra/ra6/ra6-cm33-common.dtsi:274 */
			renesas,resolution = < 0x10 >;           /* in zephyr/dts/arm/renesas/ra/ra6/ra6-cm33-common.dtsi:275 */
			status = "disabled";                     /* in zephyr/dts/arm/renesas/ra/ra6/ra6-cm33-common.dtsi:276 */

			/* node '/soc/agt@400e8400/counter' defined in zephyr/dts/arm/renesas/ra/ra6/ra6-cm33-common.dtsi:278 */
			counter {
				compatible = "renesas,ra-agt-counter"; /* in zephyr/dts/arm/renesas/ra/ra6/ra6-cm33-common.dtsi:279 */
				status = "disabled";                   /* in zephyr/dts/arm/renesas/ra/ra6/ra6-cm33-common.dtsi:280 */
			};
		};

		/* node '/soc/agt@400e8500' defined in zephyr/dts/arm/renesas/ra/ra6/ra6-cm33-common.dtsi:284 */
		agt5: agt@400e8500 {
			compatible = "renesas,ra-agt";           /* in zephyr/dts/arm/renesas/ra/ra6/ra6-cm33-common.dtsi:285 */
			channel = < 0x5 >;                       /* in zephyr/dts/arm/renesas/ra/ra6/ra6-cm33-common.dtsi:286 */
			reg = < 0x400e8500 0x100 >;              /* in zephyr/dts/arm/renesas/ra/ra6/ra6-cm33-common.dtsi:287 */
			renesas,count-source = "AGT_CLOCK_LOCO"; /* in zephyr/dts/arm/renesas/ra/ra6/ra6-cm33-common.dtsi:288 */
			renesas,prescaler = < 0x0 >;             /* in zephyr/dts/arm/renesas/ra/ra6/ra6-cm33-common.dtsi:289 */
			renesas,resolution = < 0x10 >;           /* in zephyr/dts/arm/renesas/ra/ra6/ra6-cm33-common.dtsi:290 */
			status = "disabled";                     /* in zephyr/dts/arm/renesas/ra/ra6/ra6-cm33-common.dtsi:291 */

			/* node '/soc/agt@400e8500/counter' defined in zephyr/dts/arm/renesas/ra/ra6/ra6-cm33-common.dtsi:293 */
			counter {
				compatible = "renesas,ra-agt-counter"; /* in zephyr/dts/arm/renesas/ra/ra6/ra6-cm33-common.dtsi:294 */
				status = "disabled";                   /* in zephyr/dts/arm/renesas/ra/ra6/ra6-cm33-common.dtsi:295 */
			};
		};

		/* node '/soc/adc@40170000' defined in zephyr/dts/arm/renesas/ra/ra6/ra6-cm33-common.dtsi:299 */
		adc0: adc@40170000 {
			compatible = "renesas,ra-adc";       /* in zephyr/dts/arm/renesas/ra/ra6/ra6-cm33-common.dtsi:300 */
			interrupts = < 0x26 0x1 >;           /* in zephyr/dts/arm/renesas/ra/ra6/ra6-cm33-common.dtsi:301 */
			interrupt-names = "scanend";         /* in zephyr/dts/arm/renesas/ra/ra6/ra6-cm33-common.dtsi:302 */
			reg = < 0x40170000 0x100 >;          /* in zephyr/dts/arm/renesas/ra/ra6/ra6-cm33-common.dtsi:303 */
			#io-channel-cells = < 0x1 >;         /* in zephyr/dts/arm/renesas/ra/ra6/ra6-cm33-common.dtsi:304 */
			vref-mv = < 0xce4 >;                 /* in zephyr/dts/arm/renesas/ra/ra6/ra6-cm33-common.dtsi:305 */
			channel-available-mask = < 0x31ff >; /* in zephyr/dts/arm/renesas/ra/ra6/r7fa6e10x.dtsi:135 */
			status = "okay";                     /* in zephyr/boards/renesas/fpb_ra6e1/fpb_ra6e1.dts:121 */
			pinctrl-0 = < &adc0_default >;       /* in zephyr/boards/renesas/fpb_ra6e1/fpb_ra6e1.dts:122 */
			pinctrl-names = "default";           /* in zephyr/boards/renesas/fpb_ra6e1/fpb_ra6e1.dts:123 */
		};

		/* node '/soc/crc@40108000' defined in zephyr/dts/arm/renesas/ra/ra6/ra6-cm33-common.dtsi:319 */
		crc: crc@40108000 {
			compatible = "renesas,ra-crc"; /* in zephyr/dts/arm/renesas/ra/ra6/ra6-cm33-common.dtsi:320 */
			reg = < 0x40108000 0x1000 >;   /* in zephyr/dts/arm/renesas/ra/ra6/ra6-cm33-common.dtsi:321 */
			clocks = < &pclka 0x2 0x1 >;   /* in zephyr/dts/arm/renesas/ra/ra6/ra6-cm33-common.dtsi:322 */
			status = "okay";               /* in zephyr/boards/renesas/fpb_ra6e1/fpb_ra6e1.dts:154 */
		};

		/* node '/soc/dac_global@40171000' defined in zephyr/dts/arm/renesas/ra/ra6/ra6-cm33-common.dtsi:326 */
		dac_global: dac_global@40171000 {
			compatible = "renesas,ra-dac-global"; /* in zephyr/dts/arm/renesas/ra/ra6/ra6-cm33-common.dtsi:327 */
			reg = < 0x40171000 0x10c4 >;          /* in zephyr/dts/arm/renesas/ra/ra6/ra6-cm33-common.dtsi:328 */
			#address-cells = < 0x1 >;             /* in zephyr/dts/arm/renesas/ra/ra6/ra6-cm33-common.dtsi:329 */
			#size-cells = < 0x0 >;                /* in zephyr/dts/arm/renesas/ra/ra6/ra6-cm33-common.dtsi:330 */
			has-output-amplifier;                 /* in zephyr/dts/arm/renesas/ra/ra6/r7fa6e10x.dtsi:456 */

			/* node '/soc/dac_global@40171000/dac@0' defined in zephyr/dts/arm/renesas/ra/ra6/ra6-cm33-common.dtsi:332 */
			dac0: dac@0 {
				compatible = "renesas,ra-dac"; /* in zephyr/dts/arm/renesas/ra/ra6/ra6-cm33-common.dtsi:333 */
				#io-channel-cells = < 0x1 >;   /* in zephyr/dts/arm/renesas/ra/ra6/ra6-cm33-common.dtsi:334 */
				reg = < 0x0 >;                 /* in zephyr/dts/arm/renesas/ra/ra6/ra6-cm33-common.dtsi:335 */
				pinctrl-0 = < &dac0_default >; /* in zephyr/boards/renesas/fpb_ra6e1/fpb_ra6e1.dts:127 */
				pinctrl-names = "default";     /* in zephyr/boards/renesas/fpb_ra6e1/fpb_ra6e1.dts:128 */
				status = "okay";               /* in zephyr/boards/renesas/fpb_ra6e1/fpb_ra6e1.dts:129 */
			};
		};

		/* node '/soc/usbfs@40090000' defined in zephyr/dts/arm/renesas/ra/ra6/ra6-cm33-common.dtsi:347 */
		usbfs: usbfs@40090000 {
			compatible = "renesas,ra-usbfs"; /* in zephyr/dts/arm/renesas/ra/ra6/ra6-cm33-common.dtsi:348 */
			reg = < 0x40090000 0x2000 >;     /* in zephyr/dts/arm/renesas/ra/ra6/ra6-cm33-common.dtsi:349 */
			interrupts = < 0x37 0xc >,
			             < 0x38 0xc >;       /* in zephyr/dts/arm/renesas/ra/ra6/ra6-cm33-common.dtsi:350 */
			interrupt-names = "usbfs-i",
			                  "usbfs-r";     /* in zephyr/dts/arm/renesas/ra/ra6/ra6-cm33-common.dtsi:351 */
			num-bidir-endpoints = < 0xa >;   /* in zephyr/dts/arm/renesas/ra/ra6/ra6-cm33-common.dtsi:352 */
			phys = < &usbfs_phy >;           /* in zephyr/dts/arm/renesas/ra/ra6/ra6-cm33-common.dtsi:353 */
			phys-clock = < &uclk >;          /* in zephyr/dts/arm/renesas/ra/ra6/ra6-cm33-common.dtsi:354 */
			status = "disabled";             /* in zephyr/dts/arm/renesas/ra/ra6/ra6-cm33-common.dtsi:355 */

			/* node '/soc/usbfs@40090000/udc' defined in zephyr/dts/arm/renesas/ra/ra6/ra6-cm33-common.dtsi:357 */
			udc {
				compatible = "renesas,ra-udc"; /* in zephyr/dts/arm/renesas/ra/ra6/ra6-cm33-common.dtsi:358 */
				status = "disabled";           /* in zephyr/dts/arm/renesas/ra/ra6/ra6-cm33-common.dtsi:359 */
			};
		};

		/* node '/soc/flash-controller@407e0000' defined in zephyr/dts/arm/renesas/ra/ra6/ra6-cm33-common.dtsi:363 */
		flash: flash-controller@407e0000 {
			compatible = "renesas,ra-flash-hp-controller"; /* in zephyr/dts/arm/renesas/ra/ra6/ra6-cm33-common.dtsi:364 */
			reg = < 0x407e0000 0x10000 >;                  /* in zephyr/dts/arm/renesas/ra/ra6/ra6-cm33-common.dtsi:365 */
			#address-cells = < 0x1 >;                      /* in zephyr/dts/arm/renesas/ra/ra6/ra6-cm33-common.dtsi:366 */
			#size-cells = < 0x1 >;                         /* in zephyr/dts/arm/renesas/ra/ra6/ra6-cm33-common.dtsi:367 */
			interrupts = < 0x31 0x1 >,
			             < 0x32 0x1 >;                     /* in zephyr/dts/arm/renesas/ra/ra6/ra6-cm33-common.dtsi:368 */
			interrupt-names = "frdyi",
			                  "fiferr";                    /* in zephyr/dts/arm/renesas/ra/ra6/ra6-cm33-common.dtsi:369 */
			flash-hardware-version = < 0x28 >;             /* in zephyr/dts/arm/renesas/ra/ra6/r7fa6e10f2cfp.dtsi:12 */
			#erase-block-cells = < 0x2 >;                  /* in zephyr/dts/arm/renesas/ra/ra6/r7fa6e10f2cfp.dtsi:13 */
			phandle = < 0x1c >;                            /* in zephyr/dts/arm/renesas/ra/ra6/r7fa6e10f2cfp.dtsi:20 */

			/* node '/soc/flash-controller@407e0000/flash@0' defined in zephyr/dts/arm/renesas/ra/ra6/r7fa6e10f2cfp.dtsi:15 */
			flash0: flash@0 {
				compatible = "renesas,ra-nv-code-flash"; /* in zephyr/dts/arm/renesas/ra/ra6/r7fa6e10f2cfp.dtsi:16 */
				reg = < 0x0 0x100000 >;                  /* in zephyr/dts/arm/renesas/ra/ra6/r7fa6e10f2cfp.dtsi:17 */
				write-block-size = < 0x80 >;             /* in zephyr/dts/arm/renesas/ra/ra6/r7fa6e10f2cfp.dtsi:18 */
				erase-block-size = < 0x8000 >;           /* in zephyr/dts/arm/renesas/ra/ra6/r7fa6e10f2cfp.dtsi:19 */
				erase-blocks = < &flash 0x8 0x2000 >,
				               < &flash 0x1e 0x8000 >;   /* in zephyr/dts/arm/renesas/ra/ra6/r7fa6e10f2cfp.dtsi:20 */
				programming-enable;                      /* in zephyr/dts/arm/renesas/ra/ra6/r7fa6e10f2cfp.dtsi:21 */
			};

			/* node '/soc/flash-controller@407e0000/flash@8000000' defined in zephyr/dts/arm/renesas/ra/ra6/r7fa6e10f2cfp.dtsi:24 */
			flash1: flash@8000000 {
				compatible = "renesas,ra-nv-data-flash"; /* in zephyr/dts/arm/renesas/ra/ra6/r7fa6e10f2cfp.dtsi:25 */
				reg = < 0x8000000 0x2000 >;              /* in zephyr/dts/arm/renesas/ra/ra6/r7fa6e10f2cfp.dtsi:26 */
				write-block-size = < 0x4 >;              /* in zephyr/dts/arm/renesas/ra/ra6/r7fa6e10f2cfp.dtsi:27 */
				erase-block-size = < 0x40 >;             /* in zephyr/dts/arm/renesas/ra/ra6/r7fa6e10f2cfp.dtsi:28 */
				programming-enable;                      /* in zephyr/dts/arm/renesas/ra/ra6/r7fa6e10f2cfp.dtsi:29 */
				erase-value-undefined;                   /* in zephyr/dts/arm/renesas/ra/ra6/r7fa6e10f2cfp.dtsi:30 */

				/* node '/soc/flash-controller@407e0000/flash@8000000/partitions' defined in zephyr/boards/renesas/fpb_ra6e1/fpb_ra6e1.dts:108 */
				partitions {
					compatible = "fixed-partitions"; /* in zephyr/boards/renesas/fpb_ra6e1/fpb_ra6e1.dts:109 */
					#address-cells = < 0x1 >;        /* in zephyr/boards/renesas/fpb_ra6e1/fpb_ra6e1.dts:110 */
					#size-cells = < 0x1 >;           /* in zephyr/boards/renesas/fpb_ra6e1/fpb_ra6e1.dts:111 */

					/* node '/soc/flash-controller@407e0000/flash@8000000/partitions/partition@0' defined in zephyr/boards/renesas/fpb_ra6e1/fpb_ra6e1.dts:113 */
					storage_partition: partition@0 {
						label = "storage";    /* in zephyr/boards/renesas/fpb_ra6e1/fpb_ra6e1.dts:114 */
						reg = < 0x0 0x2000 >; /* in zephyr/boards/renesas/fpb_ra6e1/fpb_ra6e1.dts:115 */
					};
				};
			};
		};

		/* node '/soc/external-interrupt@40006000' defined in zephyr/dts/arm/renesas/ra/ra6/ra6-cm33-common.dtsi:372 */
		port_irq0: external-interrupt@40006000 {
			compatible = "renesas,ra-external-interrupt"; /* in zephyr/dts/arm/renesas/ra/ra6/ra6-cm33-common.dtsi:373 */
			reg = < 0x40006000 0x1 >;                     /* in zephyr/dts/arm/renesas/ra/ra6/ra6-cm33-common.dtsi:374 */
			channel = < 0x0 >;                            /* in zephyr/dts/arm/renesas/ra/ra6/ra6-cm33-common.dtsi:375 */
			renesas,sample-clock-div = < 0x40 >;          /* in zephyr/dts/arm/renesas/ra/ra6/ra6-cm33-common.dtsi:376 */
			#port-irq-cells = < 0x0 >;                    /* in zephyr/dts/arm/renesas/ra/ra6/ra6-cm33-common.dtsi:377 */
			status = "disabled";                          /* in zephyr/dts/arm/renesas/ra/ra6/ra6-cm33-common.dtsi:378 */
			phandle = < 0xb >;                            /* in zephyr/dts/arm/renesas/ra/ra6/r7fa6e10x.dtsi:375 */
		};

		/* node '/soc/external-interrupt@40006001' defined in zephyr/dts/arm/renesas/ra/ra6/ra6-cm33-common.dtsi:381 */
		port_irq1: external-interrupt@40006001 {
			compatible = "renesas,ra-external-interrupt"; /* in zephyr/dts/arm/renesas/ra/ra6/ra6-cm33-common.dtsi:382 */
			reg = < 0x40006001 0x1 >;                     /* in zephyr/dts/arm/renesas/ra/ra6/ra6-cm33-common.dtsi:383 */
			channel = < 0x1 >;                            /* in zephyr/dts/arm/renesas/ra/ra6/ra6-cm33-common.dtsi:384 */
			renesas,sample-clock-div = < 0x40 >;          /* in zephyr/dts/arm/renesas/ra/ra6/ra6-cm33-common.dtsi:385 */
			#port-irq-cells = < 0x0 >;                    /* in zephyr/dts/arm/renesas/ra/ra6/ra6-cm33-common.dtsi:386 */
			interrupts = < 0x29 0xc >;                    /* in zephyr/boards/renesas/fpb_ra6e1/fpb_ra6e1.dts:133 */
			status = "okay";                              /* in zephyr/boards/renesas/fpb_ra6e1/fpb_ra6e1.dts:134 */
			phandle = < 0xc >;                            /* in zephyr/dts/arm/renesas/ra/ra6/r7fa6e10x.dtsi:375 */
		};

		/* node '/soc/external-interrupt@40006002' defined in zephyr/dts/arm/renesas/ra/ra6/ra6-cm33-common.dtsi:390 */
		port_irq2: external-interrupt@40006002 {
			compatible = "renesas,ra-external-interrupt"; /* in zephyr/dts/arm/renesas/ra/ra6/ra6-cm33-common.dtsi:391 */
			reg = < 0x40006002 0x1 >;                     /* in zephyr/dts/arm/renesas/ra/ra6/ra6-cm33-common.dtsi:392 */
			channel = < 0x2 >;                            /* in zephyr/dts/arm/renesas/ra/ra6/ra6-cm33-common.dtsi:393 */
			renesas,sample-clock-div = < 0x40 >;          /* in zephyr/dts/arm/renesas/ra/ra6/ra6-cm33-common.dtsi:394 */
			#port-irq-cells = < 0x0 >;                    /* in zephyr/dts/arm/renesas/ra/ra6/ra6-cm33-common.dtsi:395 */
			status = "disabled";                          /* in zephyr/dts/arm/renesas/ra/ra6/ra6-cm33-common.dtsi:396 */
			phandle = < 0xd >;                            /* in zephyr/dts/arm/renesas/ra/ra6/r7fa6e10x.dtsi:375 */
		};

		/* node '/soc/external-interrupt@40006003' defined in zephyr/dts/arm/renesas/ra/ra6/ra6-cm33-common.dtsi:399 */
		port_irq3: external-interrupt@40006003 {
			compatible = "renesas,ra-external-interrupt"; /* in zephyr/dts/arm/renesas/ra/ra6/ra6-cm33-common.dtsi:400 */
			reg = < 0x40006003 0x1 >;                     /* in zephyr/dts/arm/renesas/ra/ra6/ra6-cm33-common.dtsi:401 */
			channel = < 0x3 >;                            /* in zephyr/dts/arm/renesas/ra/ra6/ra6-cm33-common.dtsi:402 */
			renesas,sample-clock-div = < 0x40 >;          /* in zephyr/dts/arm/renesas/ra/ra6/ra6-cm33-common.dtsi:403 */
			#port-irq-cells = < 0x0 >;                    /* in zephyr/dts/arm/renesas/ra/ra6/ra6-cm33-common.dtsi:404 */
			status = "disabled";                          /* in zephyr/dts/arm/renesas/ra/ra6/ra6-cm33-common.dtsi:405 */
			phandle = < 0xe >;                            /* in zephyr/dts/arm/renesas/ra/ra6/r7fa6e10x.dtsi:375 */
		};

		/* node '/soc/external-interrupt@40006004' defined in zephyr/dts/arm/renesas/ra/ra6/ra6-cm33-common.dtsi:408 */
		port_irq4: external-interrupt@40006004 {
			compatible = "renesas,ra-external-interrupt"; /* in zephyr/dts/arm/renesas/ra/ra6/ra6-cm33-common.dtsi:409 */
			reg = < 0x40006004 0x1 >;                     /* in zephyr/dts/arm/renesas/ra/ra6/ra6-cm33-common.dtsi:410 */
			channel = < 0x4 >;                            /* in zephyr/dts/arm/renesas/ra/ra6/ra6-cm33-common.dtsi:411 */
			renesas,sample-clock-div = < 0x40 >;          /* in zephyr/dts/arm/renesas/ra/ra6/ra6-cm33-common.dtsi:412 */
			#port-irq-cells = < 0x0 >;                    /* in zephyr/dts/arm/renesas/ra/ra6/ra6-cm33-common.dtsi:413 */
			status = "disabled";                          /* in zephyr/dts/arm/renesas/ra/ra6/ra6-cm33-common.dtsi:414 */
			phandle = < 0xf >;                            /* in zephyr/dts/arm/renesas/ra/ra6/r7fa6e10x.dtsi:375 */
		};

		/* node '/soc/external-interrupt@40006005' defined in zephyr/dts/arm/renesas/ra/ra6/ra6-cm33-common.dtsi:417 */
		port_irq5: external-interrupt@40006005 {
			compatible = "renesas,ra-external-interrupt"; /* in zephyr/dts/arm/renesas/ra/ra6/ra6-cm33-common.dtsi:418 */
			reg = < 0x40006005 0x1 >;                     /* in zephyr/dts/arm/renesas/ra/ra6/ra6-cm33-common.dtsi:419 */
			channel = < 0x5 >;                            /* in zephyr/dts/arm/renesas/ra/ra6/ra6-cm33-common.dtsi:420 */
			renesas,sample-clock-div = < 0x40 >;          /* in zephyr/dts/arm/renesas/ra/ra6/ra6-cm33-common.dtsi:421 */
			#port-irq-cells = < 0x0 >;                    /* in zephyr/dts/arm/renesas/ra/ra6/ra6-cm33-common.dtsi:422 */
			status = "disabled";                          /* in zephyr/dts/arm/renesas/ra/ra6/ra6-cm33-common.dtsi:423 */
			phandle = < 0x10 >;                           /* in zephyr/dts/arm/renesas/ra/ra6/r7fa6e10x.dtsi:403 */
		};

		/* node '/soc/external-interrupt@40006006' defined in zephyr/dts/arm/renesas/ra/ra6/ra6-cm33-common.dtsi:426 */
		port_irq6: external-interrupt@40006006 {
			compatible = "renesas,ra-external-interrupt"; /* in zephyr/dts/arm/renesas/ra/ra6/ra6-cm33-common.dtsi:427 */
			reg = < 0x40006006 0x1 >;                     /* in zephyr/dts/arm/renesas/ra/ra6/ra6-cm33-common.dtsi:428 */
			channel = < 0x6 >;                            /* in zephyr/dts/arm/renesas/ra/ra6/ra6-cm33-common.dtsi:429 */
			renesas,sample-clock-div = < 0x40 >;          /* in zephyr/dts/arm/renesas/ra/ra6/ra6-cm33-common.dtsi:430 */
			#port-irq-cells = < 0x0 >;                    /* in zephyr/dts/arm/renesas/ra/ra6/ra6-cm33-common.dtsi:431 */
			status = "disabled";                          /* in zephyr/dts/arm/renesas/ra/ra6/ra6-cm33-common.dtsi:432 */
			phandle = < 0x3 >;                            /* in zephyr/dts/arm/renesas/ra/ra6/r7fa6e10x.dtsi:353 */
		};

		/* node '/soc/external-interrupt@40006007' defined in zephyr/dts/arm/renesas/ra/ra6/ra6-cm33-common.dtsi:435 */
		port_irq7: external-interrupt@40006007 {
			compatible = "renesas,ra-external-interrupt"; /* in zephyr/dts/arm/renesas/ra/ra6/ra6-cm33-common.dtsi:436 */
			reg = < 0x40006007 0x1 >;                     /* in zephyr/dts/arm/renesas/ra/ra6/ra6-cm33-common.dtsi:437 */
			channel = < 0x7 >;                            /* in zephyr/dts/arm/renesas/ra/ra6/ra6-cm33-common.dtsi:438 */
			renesas,sample-clock-div = < 0x40 >;          /* in zephyr/dts/arm/renesas/ra/ra6/ra6-cm33-common.dtsi:439 */
			#port-irq-cells = < 0x0 >;                    /* in zephyr/dts/arm/renesas/ra/ra6/ra6-cm33-common.dtsi:440 */
			status = "disabled";                          /* in zephyr/dts/arm/renesas/ra/ra6/ra6-cm33-common.dtsi:441 */
			phandle = < 0x4 >;                            /* in zephyr/dts/arm/renesas/ra/ra6/r7fa6e10x.dtsi:353 */
		};

		/* node '/soc/external-interrupt@40006008' defined in zephyr/dts/arm/renesas/ra/ra6/ra6-cm33-common.dtsi:444 */
		port_irq8: external-interrupt@40006008 {
			compatible = "renesas,ra-external-interrupt"; /* in zephyr/dts/arm/renesas/ra/ra6/ra6-cm33-common.dtsi:445 */
			reg = < 0x40006008 0x1 >;                     /* in zephyr/dts/arm/renesas/ra/ra6/ra6-cm33-common.dtsi:446 */
			channel = < 0x8 >;                            /* in zephyr/dts/arm/renesas/ra/ra6/ra6-cm33-common.dtsi:447 */
			renesas,sample-clock-div = < 0x40 >;          /* in zephyr/dts/arm/renesas/ra/ra6/ra6-cm33-common.dtsi:448 */
			#port-irq-cells = < 0x0 >;                    /* in zephyr/dts/arm/renesas/ra/ra6/ra6-cm33-common.dtsi:449 */
			status = "disabled";                          /* in zephyr/dts/arm/renesas/ra/ra6/ra6-cm33-common.dtsi:450 */
			phandle = < 0x5 >;                            /* in zephyr/dts/arm/renesas/ra/ra6/r7fa6e10x.dtsi:353 */
		};

		/* node '/soc/external-interrupt@40006009' defined in zephyr/dts/arm/renesas/ra/ra6/ra6-cm33-common.dtsi:453 */
		port_irq9: external-interrupt@40006009 {
			compatible = "renesas,ra-external-interrupt"; /* in zephyr/dts/arm/renesas/ra/ra6/ra6-cm33-common.dtsi:454 */
			reg = < 0x40006009 0x1 >;                     /* in zephyr/dts/arm/renesas/ra/ra6/ra6-cm33-common.dtsi:455 */
			channel = < 0x9 >;                            /* in zephyr/dts/arm/renesas/ra/ra6/ra6-cm33-common.dtsi:456 */
			renesas,sample-clock-div = < 0x40 >;          /* in zephyr/dts/arm/renesas/ra/ra6/ra6-cm33-common.dtsi:457 */
			#port-irq-cells = < 0x0 >;                    /* in zephyr/dts/arm/renesas/ra/ra6/ra6-cm33-common.dtsi:458 */
			status = "disabled";                          /* in zephyr/dts/arm/renesas/ra/ra6/ra6-cm33-common.dtsi:459 */
			phandle = < 0x6 >;                            /* in zephyr/dts/arm/renesas/ra/ra6/r7fa6e10x.dtsi:353 */
		};

		/* node '/soc/external-interrupt@4000600a' defined in zephyr/dts/arm/renesas/ra/ra6/ra6-cm33-common.dtsi:462 */
		port_irq10: external-interrupt@4000600a {
			compatible = "renesas,ra-external-interrupt"; /* in zephyr/dts/arm/renesas/ra/ra6/ra6-cm33-common.dtsi:463 */
			reg = < 0x4000600a 0x1 >;                     /* in zephyr/dts/arm/renesas/ra/ra6/ra6-cm33-common.dtsi:464 */
			channel = < 0xa >;                            /* in zephyr/dts/arm/renesas/ra/ra6/ra6-cm33-common.dtsi:465 */
			renesas,sample-clock-div = < 0x40 >;          /* in zephyr/dts/arm/renesas/ra/ra6/ra6-cm33-common.dtsi:466 */
			#port-irq-cells = < 0x0 >;                    /* in zephyr/dts/arm/renesas/ra/ra6/ra6-cm33-common.dtsi:467 */
			status = "disabled";                          /* in zephyr/dts/arm/renesas/ra/ra6/ra6-cm33-common.dtsi:468 */
			phandle = < 0x7 >;                            /* in zephyr/dts/arm/renesas/ra/ra6/r7fa6e10x.dtsi:353 */
		};

		/* node '/soc/external-interrupt@4000600b' defined in zephyr/dts/arm/renesas/ra/ra6/ra6-cm33-common.dtsi:471 */
		port_irq11: external-interrupt@4000600b {
			compatible = "renesas,ra-external-interrupt"; /* in zephyr/dts/arm/renesas/ra/ra6/ra6-cm33-common.dtsi:472 */
			reg = < 0x4000600b 0x1 >;                     /* in zephyr/dts/arm/renesas/ra/ra6/ra6-cm33-common.dtsi:473 */
			channel = < 0xb >;                            /* in zephyr/dts/arm/renesas/ra/ra6/ra6-cm33-common.dtsi:474 */
			renesas,sample-clock-div = < 0x40 >;          /* in zephyr/dts/arm/renesas/ra/ra6/ra6-cm33-common.dtsi:475 */
			#port-irq-cells = < 0x0 >;                    /* in zephyr/dts/arm/renesas/ra/ra6/ra6-cm33-common.dtsi:476 */
			status = "disabled";                          /* in zephyr/dts/arm/renesas/ra/ra6/ra6-cm33-common.dtsi:477 */
			phandle = < 0x8 >;                            /* in zephyr/dts/arm/renesas/ra/ra6/r7fa6e10x.dtsi:353 */
		};

		/* node '/soc/external-interrupt@4000600c' defined in zephyr/dts/arm/renesas/ra/ra6/ra6-cm33-common.dtsi:480 */
		port_irq12: external-interrupt@4000600c {
			compatible = "renesas,ra-external-interrupt"; /* in zephyr/dts/arm/renesas/ra/ra6/ra6-cm33-common.dtsi:481 */
			reg = < 0x4000600c 0x1 >;                     /* in zephyr/dts/arm/renesas/ra/ra6/ra6-cm33-common.dtsi:482 */
			channel = < 0xc >;                            /* in zephyr/dts/arm/renesas/ra/ra6/ra6-cm33-common.dtsi:483 */
			renesas,sample-clock-div = < 0x40 >;          /* in zephyr/dts/arm/renesas/ra/ra6/ra6-cm33-common.dtsi:484 */
			#port-irq-cells = < 0x0 >;                    /* in zephyr/dts/arm/renesas/ra/ra6/ra6-cm33-common.dtsi:485 */
			status = "disabled";                          /* in zephyr/dts/arm/renesas/ra/ra6/ra6-cm33-common.dtsi:486 */
			phandle = < 0x9 >;                            /* in zephyr/dts/arm/renesas/ra/ra6/r7fa6e10x.dtsi:353 */
		};

		/* node '/soc/external-interrupt@4000600d' defined in zephyr/dts/arm/renesas/ra/ra6/ra6-cm33-common.dtsi:489 */
		port_irq13: external-interrupt@4000600d {
			compatible = "renesas,ra-external-interrupt"; /* in zephyr/dts/arm/renesas/ra/ra6/ra6-cm33-common.dtsi:490 */
			reg = < 0x4000600d 0x1 >;                     /* in zephyr/dts/arm/renesas/ra/ra6/ra6-cm33-common.dtsi:491 */
			channel = < 0xd >;                            /* in zephyr/dts/arm/renesas/ra/ra6/ra6-cm33-common.dtsi:492 */
			renesas,sample-clock-div = < 0x40 >;          /* in zephyr/dts/arm/renesas/ra/ra6/ra6-cm33-common.dtsi:493 */
			#port-irq-cells = < 0x0 >;                    /* in zephyr/dts/arm/renesas/ra/ra6/ra6-cm33-common.dtsi:494 */
			status = "disabled";                          /* in zephyr/dts/arm/renesas/ra/ra6/ra6-cm33-common.dtsi:495 */
			phandle = < 0xa >;                            /* in zephyr/dts/arm/renesas/ra/ra6/r7fa6e10x.dtsi:353 */
		};

		/* node '/soc/external-interrupt@4000600e' defined in zephyr/dts/arm/renesas/ra/ra6/ra6-cm33-common.dtsi:498 */
		port_irq14: external-interrupt@4000600e {
			compatible = "renesas,ra-external-interrupt"; /* in zephyr/dts/arm/renesas/ra/ra6/ra6-cm33-common.dtsi:499 */
			reg = < 0x4000600e 0x1 >;                     /* in zephyr/dts/arm/renesas/ra/ra6/ra6-cm33-common.dtsi:500 */
			channel = < 0xe >;                            /* in zephyr/dts/arm/renesas/ra/ra6/ra6-cm33-common.dtsi:501 */
			renesas,sample-clock-div = < 0x40 >;          /* in zephyr/dts/arm/renesas/ra/ra6/ra6-cm33-common.dtsi:502 */
			#port-irq-cells = < 0x0 >;                    /* in zephyr/dts/arm/renesas/ra/ra6/ra6-cm33-common.dtsi:503 */
			status = "disabled";                          /* in zephyr/dts/arm/renesas/ra/ra6/ra6-cm33-common.dtsi:504 */
			phandle = < 0x11 >;                           /* in zephyr/dts/arm/renesas/ra/ra6/r7fa6e10x.dtsi:416 */
		};

		/* node '/soc/external-interrupt@4000600f' defined in zephyr/dts/arm/renesas/ra/ra6/ra6-cm33-common.dtsi:507 */
		port_irq15: external-interrupt@4000600f {
			compatible = "renesas,ra-external-interrupt"; /* in zephyr/dts/arm/renesas/ra/ra6/ra6-cm33-common.dtsi:508 */
			reg = < 0x4000600f 0x1 >;                     /* in zephyr/dts/arm/renesas/ra/ra6/ra6-cm33-common.dtsi:509 */
			channel = < 0xf >;                            /* in zephyr/dts/arm/renesas/ra/ra6/ra6-cm33-common.dtsi:510 */
			renesas,sample-clock-div = < 0x40 >;          /* in zephyr/dts/arm/renesas/ra/ra6/ra6-cm33-common.dtsi:511 */
			#port-irq-cells = < 0x0 >;                    /* in zephyr/dts/arm/renesas/ra/ra6/ra6-cm33-common.dtsi:512 */
			status = "disabled";                          /* in zephyr/dts/arm/renesas/ra/ra6/ra6-cm33-common.dtsi:513 */
			phandle = < 0x12 >;                           /* in zephyr/dts/arm/renesas/ra/ra6/r7fa6e10x.dtsi:416 */
		};

		/* node '/soc/pwm1@40169100' defined in zephyr/dts/arm/renesas/ra/ra6/ra6-cm33-common.dtsi:516 */
		pwm1: pwm1@40169100 {
			compatible = "renesas,ra-pwm"; /* in zephyr/dts/arm/renesas/ra/ra6/ra6-cm33-common.dtsi:517 */
			divider = < 0x0 >;             /* in zephyr/dts/arm/renesas/ra/ra6/ra6-cm33-common.dtsi:518 */
			channel = < 0x1 >;             /* in zephyr/dts/arm/renesas/ra/ra6/ra6-cm33-common.dtsi:519 */
			clocks = < &pclkd 0x4 0x1e >;  /* in zephyr/dts/arm/renesas/ra/ra6/ra6-cm33-common.dtsi:520 */
			reg = < 0x40169100 0x100 >;    /* in zephyr/dts/arm/renesas/ra/ra6/ra6-cm33-common.dtsi:521 */
			#pwm-cells = < 0x3 >;          /* in zephyr/dts/arm/renesas/ra/ra6/ra6-cm33-common.dtsi:522 */
			pinctrl-0 = < &pwm1_default >; /* in zephyr/boards/renesas/fpb_ra6e1/fpb_ra6e1.dts:138 */
			pinctrl-names = "default";     /* in zephyr/boards/renesas/fpb_ra6e1/fpb_ra6e1.dts:139 */
			interrupts = < 0x3f 0x1 >,
			             < 0x40 0x1 >;     /* in zephyr/boards/renesas/fpb_ra6e1/fpb_ra6e1.dts:140 */
			interrupt-names = "gtioca",
			                  "overflow";  /* in zephyr/boards/renesas/fpb_ra6e1/fpb_ra6e1.dts:141 */
			status = "okay";               /* in zephyr/boards/renesas/fpb_ra6e1/fpb_ra6e1.dts:142 */
		};

		/* node '/soc/pwm2@40169200' defined in zephyr/dts/arm/renesas/ra/ra6/ra6-cm33-common.dtsi:526 */
		pwm2: pwm2@40169200 {
			compatible = "renesas,ra-pwm"; /* in zephyr/dts/arm/renesas/ra/ra6/ra6-cm33-common.dtsi:527 */
			divider = < 0x0 >;             /* in zephyr/dts/arm/renesas/ra/ra6/ra6-cm33-common.dtsi:528 */
			channel = < 0x2 >;             /* in zephyr/dts/arm/renesas/ra/ra6/ra6-cm33-common.dtsi:529 */
			clocks = < &pclkd 0x4 0x1d >;  /* in zephyr/dts/arm/renesas/ra/ra6/ra6-cm33-common.dtsi:530 */
			reg = < 0x40169200 0x100 >;    /* in zephyr/dts/arm/renesas/ra/ra6/ra6-cm33-common.dtsi:531 */
			#pwm-cells = < 0x3 >;          /* in zephyr/dts/arm/renesas/ra/ra6/ra6-cm33-common.dtsi:532 */
			status = "disabled";           /* in zephyr/dts/arm/renesas/ra/ra6/ra6-cm33-common.dtsi:533 */
		};

		/* node '/soc/pwm4@40169400' defined in zephyr/dts/arm/renesas/ra/ra6/ra6-cm33-common.dtsi:536 */
		pwm4: pwm4@40169400 {
			compatible = "renesas,ra-pwm"; /* in zephyr/dts/arm/renesas/ra/ra6/ra6-cm33-common.dtsi:537 */
			divider = < 0x0 >;             /* in zephyr/dts/arm/renesas/ra/ra6/ra6-cm33-common.dtsi:538 */
			channel = < 0x4 >;             /* in zephyr/dts/arm/renesas/ra/ra6/ra6-cm33-common.dtsi:539 */
			clocks = < &pclkd 0x4 0x1b >;  /* in zephyr/dts/arm/renesas/ra/ra6/ra6-cm33-common.dtsi:540 */
			reg = < 0x40169400 0x100 >;    /* in zephyr/dts/arm/renesas/ra/ra6/ra6-cm33-common.dtsi:541 */
			#pwm-cells = < 0x3 >;          /* in zephyr/dts/arm/renesas/ra/ra6/ra6-cm33-common.dtsi:542 */
			status = "disabled";           /* in zephyr/dts/arm/renesas/ra/ra6/ra6-cm33-common.dtsi:543 */
		};

		/* node '/soc/pwm5@40169500' defined in zephyr/dts/arm/renesas/ra/ra6/ra6-cm33-common.dtsi:546 */
		pwm5: pwm5@40169500 {
			compatible = "renesas,ra-pwm"; /* in zephyr/dts/arm/renesas/ra/ra6/ra6-cm33-common.dtsi:547 */
			divider = < 0x0 >;             /* in zephyr/dts/arm/renesas/ra/ra6/ra6-cm33-common.dtsi:548 */
			channel = < 0x5 >;             /* in zephyr/dts/arm/renesas/ra/ra6/ra6-cm33-common.dtsi:549 */
			clocks = < &pclkd 0x4 0x1a >;  /* in zephyr/dts/arm/renesas/ra/ra6/ra6-cm33-common.dtsi:550 */
			reg = < 0x40169500 0x100 >;    /* in zephyr/dts/arm/renesas/ra/ra6/ra6-cm33-common.dtsi:551 */
			#pwm-cells = < 0x3 >;          /* in zephyr/dts/arm/renesas/ra/ra6/ra6-cm33-common.dtsi:552 */
			status = "disabled";           /* in zephyr/dts/arm/renesas/ra/ra6/ra6-cm33-common.dtsi:553 */
		};

		/* node '/soc/wdt@40083400' defined in zephyr/dts/arm/renesas/ra/ra6/ra6-cm33-common.dtsi:556 */
		wdt: wdt@40083400 {
			compatible = "renesas,ra-wdt"; /* in zephyr/dts/arm/renesas/ra/ra6/ra6-cm33-common.dtsi:557 */
			reg = < 0x40083400 0x200 >;    /* in zephyr/dts/arm/renesas/ra/ra6/ra6-cm33-common.dtsi:558 */
			clocks = < &pclkb 0x0 0x0 >;   /* in zephyr/dts/arm/renesas/ra/ra6/ra6-cm33-common.dtsi:559 */
			status = "okay";               /* in zephyr/boards/renesas/fpb_ra6e1/fpb_ra6e1.dts:150 */
		};

		/* node '/soc/ethernet@40114100' defined in zephyr/dts/arm/renesas/ra/ra6/ra6-cm33-common.dtsi:563 */
		eth: ethernet@40114100 {
			compatible = "renesas,ra-ethernet";        /* in zephyr/dts/arm/renesas/ra/ra6/ra6-cm33-common.dtsi:564 */
			reg = < 0x40114100 0xfc >;                 /* in zephyr/dts/arm/renesas/ra/ra6/ra6-cm33-common.dtsi:565 */
			interrupts = < 0x33 0xc >;                 /* in zephyr/dts/arm/renesas/ra/ra6/ra6-cm33-common.dtsi:566 */
			local-mac-address = [ 00 11 22 33 44 55 ]; /* in zephyr/dts/arm/renesas/ra/ra6/ra6-cm33-common.dtsi:567 */
			phy-connection-type = "rmii";              /* in zephyr/dts/arm/renesas/ra/ra6/ra6-cm33-common.dtsi:568 */
			status = "disabled";                       /* in zephyr/dts/arm/renesas/ra/ra6/ra6-cm33-common.dtsi:569 */
		};

		/* node '/soc/mdio' defined in zephyr/dts/arm/renesas/ra/ra6/ra6-cm33-common.dtsi:572 */
		mdio: mdio {
			compatible = "renesas,ra-mdio"; /* in zephyr/dts/arm/renesas/ra/ra6/ra6-cm33-common.dtsi:573 */
			#address-cells = < 0x1 >;       /* in zephyr/dts/arm/renesas/ra/ra6/ra6-cm33-common.dtsi:574 */
			#size-cells = < 0x0 >;          /* in zephyr/dts/arm/renesas/ra/ra6/ra6-cm33-common.dtsi:575 */
			status = "disabled";            /* in zephyr/dts/arm/renesas/ra/ra6/ra6-cm33-common.dtsi:576 */
		};

		/* node '/soc/ctsua@40081000' defined in zephyr/dts/arm/renesas/ra/ra6/ra6-cm33-common.dtsi:579 */
		ctsu: ctsua@40081000 {
			compatible = "renesas,ra-ctsu"; /* in zephyr/dts/arm/renesas/ra/ra6/ra6-cm33-common.dtsi:580 */
			reg = < 0x40081000 0x24 >;      /* in zephyr/dts/arm/renesas/ra/ra6/ra6-cm33-common.dtsi:581 */
			clocks = < &pclkb 0x2 0x3 >;    /* in zephyr/dts/arm/renesas/ra/ra6/ra6-cm33-common.dtsi:582 */
			variant = "ctsua";              /* in zephyr/dts/arm/renesas/ra/ra6/ra6-cm33-common.dtsi:583 */
			status = "disabled";            /* in zephyr/dts/arm/renesas/ra/ra6/ra6-cm33-common.dtsi:584 */
		};

		/* node '/soc/qspi0@64000000' defined in zephyr/dts/arm/renesas/ra/ra6/ra6-cm33-common.dtsi:587 */
		qspi0: qspi0@64000000 {
			compatible = "renesas,ra-qspi"; /* in zephyr/dts/arm/renesas/ra/ra6/ra6-cm33-common.dtsi:588 */
			#address-cells = < 0x1 >;       /* in zephyr/dts/arm/renesas/ra/ra6/ra6-cm33-common.dtsi:589 */
			#size-cells = < 0x1 >;          /* in zephyr/dts/arm/renesas/ra/ra6/ra6-cm33-common.dtsi:590 */
			reg = < 0x64000000 0x808 >;     /* in zephyr/dts/arm/renesas/ra/ra6/ra6-cm33-common.dtsi:591 */
			status = "disabled";            /* in zephyr/dts/arm/renesas/ra/ra6/ra6-cm33-common.dtsi:592 */
		};

		/* node '/soc/memory@20000000' defined in zephyr/dts/arm/renesas/ra/ra6/r7fa6e10x.dtsi:17 */
		sram0: memory@20000000 {
			compatible = "mmio-sram";     /* in zephyr/dts/arm/renesas/ra/ra6/r7fa6e10x.dtsi:18 */
			reg = < 0x20000000 0x40000 >; /* in zephyr/dts/arm/renesas/ra/ra6/r7fa6e10x.dtsi:19 */
		};

		/* node '/soc/gpio@400800c0' defined in zephyr/dts/arm/renesas/ra/ra6/r7fa6e10x.dtsi:22 */
		ioport6: gpio@400800c0 {
			compatible = "renesas,ra-gpio-ioport"; /* in zephyr/dts/arm/renesas/ra/ra6/r7fa6e10x.dtsi:23 */
			reg = < 0x400800c0 0x20 >;             /* in zephyr/dts/arm/renesas/ra/ra6/r7fa6e10x.dtsi:24 */
			port = < 0x6 >;                        /* in zephyr/dts/arm/renesas/ra/ra6/r7fa6e10x.dtsi:25 */
			gpio-controller;                       /* in zephyr/dts/arm/renesas/ra/ra6/r7fa6e10x.dtsi:26 */
			#gpio-cells = < 0x2 >;                 /* in zephyr/dts/arm/renesas/ra/ra6/r7fa6e10x.dtsi:27 */
			ngpios = < 0x10 >;                     /* in zephyr/dts/arm/renesas/ra/ra6/r7fa6e10x.dtsi:28 */
			status = "disabled";                   /* in zephyr/dts/arm/renesas/ra/ra6/r7fa6e10x.dtsi:29 */
		};

		/* node '/soc/gpio@400800e0' defined in zephyr/dts/arm/renesas/ra/ra6/r7fa6e10x.dtsi:32 */
		ioport7: gpio@400800e0 {
			compatible = "renesas,ra-gpio-ioport"; /* in zephyr/dts/arm/renesas/ra/ra6/r7fa6e10x.dtsi:33 */
			reg = < 0x400800e0 0x20 >;             /* in zephyr/dts/arm/renesas/ra/ra6/r7fa6e10x.dtsi:34 */
			port = < 0x7 >;                        /* in zephyr/dts/arm/renesas/ra/ra6/r7fa6e10x.dtsi:35 */
			gpio-controller;                       /* in zephyr/dts/arm/renesas/ra/ra6/r7fa6e10x.dtsi:36 */
			#gpio-cells = < 0x2 >;                 /* in zephyr/dts/arm/renesas/ra/ra6/r7fa6e10x.dtsi:37 */
			ngpios = < 0x10 >;                     /* in zephyr/dts/arm/renesas/ra/ra6/r7fa6e10x.dtsi:38 */
			status = "disabled";                   /* in zephyr/dts/arm/renesas/ra/ra6/r7fa6e10x.dtsi:39 */
			port-irqs = < &port_irq11 >;           /* in zephyr/dts/arm/renesas/ra/ra6/r7fa6e10x.dtsi:450 */
			port-irq-names = "port-irq11";         /* in zephyr/dts/arm/renesas/ra/ra6/r7fa6e10x.dtsi:451 */
			port-irq11-pins = < 0x8 >;             /* in zephyr/dts/arm/renesas/ra/ra6/r7fa6e10x.dtsi:452 */
		};

		/* node '/soc/sci1@40118100' defined in zephyr/dts/arm/renesas/ra/ra6/r7fa6e10x.dtsi:42 */
		sci1: sci1@40118100 {
			compatible = "renesas,ra-sci"; /* in zephyr/dts/arm/renesas/ra/ra6/r7fa6e10x.dtsi:43 */
			interrupts = < 0x4 0x1 >,
			             < 0x5 0x1 >,
			             < 0x6 0x1 >,
			             < 0x7 0x1 >;      /* in zephyr/dts/arm/renesas/ra/ra6/r7fa6e10x.dtsi:44 */
			interrupt-names = "rxi",
			                  "txi",
			                  "tei",
			                  "eri";       /* in zephyr/dts/arm/renesas/ra/ra6/r7fa6e10x.dtsi:45 */
			reg = < 0x40118100 0x100 >;    /* in zephyr/dts/arm/renesas/ra/ra6/r7fa6e10x.dtsi:46 */
			clocks = < &pclka 0x1 0x1e >;  /* in zephyr/dts/arm/renesas/ra/ra6/r7fa6e10x.dtsi:47 */
			status = "disabled";           /* in zephyr/dts/arm/renesas/ra/ra6/r7fa6e10x.dtsi:48 */

			/* node '/soc/sci1@40118100/uart' defined in zephyr/dts/arm/renesas/ra/ra6/r7fa6e10x.dtsi:50 */
			uart {
				compatible = "renesas,ra-sci-uart"; /* in zephyr/dts/arm/renesas/ra/ra6/r7fa6e10x.dtsi:51 */
				channel = < 0x1 >;                  /* in zephyr/dts/arm/renesas/ra/ra6/r7fa6e10x.dtsi:52 */
				status = "disabled";                /* in zephyr/dts/arm/renesas/ra/ra6/r7fa6e10x.dtsi:53 */
			};

			/* node '/soc/sci1@40118100/i2c' defined in zephyr/dts/arm/renesas/ra/ra6/r7fa6e10x.dtsi:56 */
			i2c {
				compatible = "renesas,ra-i2c-sci"; /* in zephyr/dts/arm/renesas/ra/ra6/r7fa6e10x.dtsi:57 */
				#address-cells = < 0x1 >;          /* in zephyr/dts/arm/renesas/ra/ra6/r7fa6e10x.dtsi:58 */
				#size-cells = < 0x0 >;             /* in zephyr/dts/arm/renesas/ra/ra6/r7fa6e10x.dtsi:59 */
				channel = < 0x1 >;                 /* in zephyr/dts/arm/renesas/ra/ra6/r7fa6e10x.dtsi:60 */
				status = "disabled";               /* in zephyr/dts/arm/renesas/ra/ra6/r7fa6e10x.dtsi:61 */
			};
		};

		/* node '/soc/sci2@40118200' defined in zephyr/dts/arm/renesas/ra/ra6/r7fa6e10x.dtsi:65 */
		sci2: sci2@40118200 {
			compatible = "renesas,ra-sci"; /* in zephyr/dts/arm/renesas/ra/ra6/r7fa6e10x.dtsi:66 */
			interrupts = < 0x8 0x1 >,
			             < 0x9 0x1 >,
			             < 0xa 0x1 >,
			             < 0xb 0x1 >;      /* in zephyr/dts/arm/renesas/ra/ra6/r7fa6e10x.dtsi:67 */
			interrupt-names = "rxi",
			                  "txi",
			                  "tei",
			                  "eri";       /* in zephyr/dts/arm/renesas/ra/ra6/r7fa6e10x.dtsi:68 */
			reg = < 0x40118200 0x100 >;    /* in zephyr/dts/arm/renesas/ra/ra6/r7fa6e10x.dtsi:69 */
			clocks = < &pclka 0x1 0x1d >;  /* in zephyr/dts/arm/renesas/ra/ra6/r7fa6e10x.dtsi:70 */
			status = "disabled";           /* in zephyr/dts/arm/renesas/ra/ra6/r7fa6e10x.dtsi:71 */

			/* node '/soc/sci2@40118200/uart' defined in zephyr/dts/arm/renesas/ra/ra6/r7fa6e10x.dtsi:73 */
			uart {
				compatible = "renesas,ra-sci-uart"; /* in zephyr/dts/arm/renesas/ra/ra6/r7fa6e10x.dtsi:74 */
				channel = < 0x2 >;                  /* in zephyr/dts/arm/renesas/ra/ra6/r7fa6e10x.dtsi:75 */
				status = "disabled";                /* in zephyr/dts/arm/renesas/ra/ra6/r7fa6e10x.dtsi:76 */
			};

			/* node '/soc/sci2@40118200/i2c' defined in zephyr/dts/arm/renesas/ra/ra6/r7fa6e10x.dtsi:79 */
			i2c {
				compatible = "renesas,ra-i2c-sci"; /* in zephyr/dts/arm/renesas/ra/ra6/r7fa6e10x.dtsi:80 */
				#address-cells = < 0x1 >;          /* in zephyr/dts/arm/renesas/ra/ra6/r7fa6e10x.dtsi:81 */
				#size-cells = < 0x0 >;             /* in zephyr/dts/arm/renesas/ra/ra6/r7fa6e10x.dtsi:82 */
				channel = < 0x2 >;                 /* in zephyr/dts/arm/renesas/ra/ra6/r7fa6e10x.dtsi:83 */
				status = "disabled";               /* in zephyr/dts/arm/renesas/ra/ra6/r7fa6e10x.dtsi:84 */
			};
		};

		/* node '/soc/sci3@40118300' defined in zephyr/dts/arm/renesas/ra/ra6/r7fa6e10x.dtsi:88 */
		sci3: sci3@40118300 {
			compatible = "renesas,ra-sci"; /* in zephyr/dts/arm/renesas/ra/ra6/r7fa6e10x.dtsi:89 */
			interrupts = < 0xc 0x1 >,
			             < 0xd 0x1 >,
			             < 0xe 0x1 >,
			             < 0xf 0x1 >;      /* in zephyr/dts/arm/renesas/ra/ra6/r7fa6e10x.dtsi:90 */
			interrupt-names = "rxi",
			                  "txi",
			                  "tei",
			                  "eri";       /* in zephyr/dts/arm/renesas/ra/ra6/r7fa6e10x.dtsi:91 */
			reg = < 0x40118300 0x100 >;    /* in zephyr/dts/arm/renesas/ra/ra6/r7fa6e10x.dtsi:92 */
			clocks = < &pclka 0x1 0x1c >;  /* in zephyr/dts/arm/renesas/ra/ra6/r7fa6e10x.dtsi:93 */
			status = "disabled";           /* in zephyr/dts/arm/renesas/ra/ra6/r7fa6e10x.dtsi:94 */

			/* node '/soc/sci3@40118300/uart' defined in zephyr/dts/arm/renesas/ra/ra6/r7fa6e10x.dtsi:96 */
			uart {
				compatible = "renesas,ra-sci-uart"; /* in zephyr/dts/arm/renesas/ra/ra6/r7fa6e10x.dtsi:97 */
				channel = < 0x3 >;                  /* in zephyr/dts/arm/renesas/ra/ra6/r7fa6e10x.dtsi:98 */
				status = "disabled";                /* in zephyr/dts/arm/renesas/ra/ra6/r7fa6e10x.dtsi:99 */
			};

			/* node '/soc/sci3@40118300/i2c' defined in zephyr/dts/arm/renesas/ra/ra6/r7fa6e10x.dtsi:102 */
			i2c {
				compatible = "renesas,ra-i2c-sci"; /* in zephyr/dts/arm/renesas/ra/ra6/r7fa6e10x.dtsi:103 */
				#address-cells = < 0x1 >;          /* in zephyr/dts/arm/renesas/ra/ra6/r7fa6e10x.dtsi:104 */
				#size-cells = < 0x0 >;             /* in zephyr/dts/arm/renesas/ra/ra6/r7fa6e10x.dtsi:105 */
				channel = < 0x3 >;                 /* in zephyr/dts/arm/renesas/ra/ra6/r7fa6e10x.dtsi:106 */
				status = "disabled";               /* in zephyr/dts/arm/renesas/ra/ra6/r7fa6e10x.dtsi:107 */
			};
		};

		/* node '/soc/sci4@40118400' defined in zephyr/dts/arm/renesas/ra/ra6/r7fa6e10x.dtsi:111 */
		sci4: sci4@40118400 {
			compatible = "renesas,ra-sci"; /* in zephyr/dts/arm/renesas/ra/ra6/r7fa6e10x.dtsi:112 */
			interrupts = < 0x10 0x1 >,
			             < 0x11 0x1 >,
			             < 0x12 0x1 >,
			             < 0x13 0x1 >;     /* in zephyr/dts/arm/renesas/ra/ra6/r7fa6e10x.dtsi:113 */
			interrupt-names = "rxi",
			                  "txi",
			                  "tei",
			                  "eri";       /* in zephyr/dts/arm/renesas/ra/ra6/r7fa6e10x.dtsi:114 */
			reg = < 0x40118400 0x100 >;    /* in zephyr/dts/arm/renesas/ra/ra6/r7fa6e10x.dtsi:115 */
			clocks = < &pclka 0x1 0x1b >;  /* in zephyr/dts/arm/renesas/ra/ra6/r7fa6e10x.dtsi:116 */
			status = "disabled";           /* in zephyr/dts/arm/renesas/ra/ra6/r7fa6e10x.dtsi:117 */

			/* node '/soc/sci4@40118400/uart' defined in zephyr/dts/arm/renesas/ra/ra6/r7fa6e10x.dtsi:119 */
			uart {
				compatible = "renesas,ra-sci-uart"; /* in zephyr/dts/arm/renesas/ra/ra6/r7fa6e10x.dtsi:120 */
				channel = < 0x4 >;                  /* in zephyr/dts/arm/renesas/ra/ra6/r7fa6e10x.dtsi:121 */
				status = "disabled";                /* in zephyr/dts/arm/renesas/ra/ra6/r7fa6e10x.dtsi:122 */
			};

			/* node '/soc/sci4@40118400/i2c' defined in zephyr/dts/arm/renesas/ra/ra6/r7fa6e10x.dtsi:125 */
			i2c {
				compatible = "renesas,ra-i2c-sci"; /* in zephyr/dts/arm/renesas/ra/ra6/r7fa6e10x.dtsi:126 */
				#address-cells = < 0x1 >;          /* in zephyr/dts/arm/renesas/ra/ra6/r7fa6e10x.dtsi:127 */
				#size-cells = < 0x0 >;             /* in zephyr/dts/arm/renesas/ra/ra6/r7fa6e10x.dtsi:128 */
				channel = < 0x4 >;                 /* in zephyr/dts/arm/renesas/ra/ra6/r7fa6e10x.dtsi:129 */
				status = "disabled";               /* in zephyr/dts/arm/renesas/ra/ra6/r7fa6e10x.dtsi:130 */
			};
		};

		/* node '/soc/pwm6@40169600' defined in zephyr/dts/arm/renesas/ra/ra6/r7fa6e10x.dtsi:138 */
		pwm6: pwm6@40169600 {
			compatible = "renesas,ra-pwm"; /* in zephyr/dts/arm/renesas/ra/ra6/r7fa6e10x.dtsi:139 */
			divider = < 0x0 >;             /* in zephyr/dts/arm/renesas/ra/ra6/r7fa6e10x.dtsi:140 */
			channel = < 0x6 >;             /* in zephyr/dts/arm/renesas/ra/ra6/r7fa6e10x.dtsi:141 */
			clocks = < &pclkd 0x4 0x19 >;  /* in zephyr/dts/arm/renesas/ra/ra6/r7fa6e10x.dtsi:142 */
			reg = < 0x40169600 0x100 >;    /* in zephyr/dts/arm/renesas/ra/ra6/r7fa6e10x.dtsi:143 */
			#pwm-cells = < 0x3 >;          /* in zephyr/dts/arm/renesas/ra/ra6/r7fa6e10x.dtsi:144 */
			status = "disabled";           /* in zephyr/dts/arm/renesas/ra/ra6/r7fa6e10x.dtsi:145 */
		};

		/* node '/soc/pwm7@40169700' defined in zephyr/dts/arm/renesas/ra/ra6/r7fa6e10x.dtsi:148 */
		pwm7: pwm7@40169700 {
			compatible = "renesas,ra-pwm"; /* in zephyr/dts/arm/renesas/ra/ra6/r7fa6e10x.dtsi:149 */
			divider = < 0x0 >;             /* in zephyr/dts/arm/renesas/ra/ra6/r7fa6e10x.dtsi:150 */
			channel = < 0x7 >;             /* in zephyr/dts/arm/renesas/ra/ra6/r7fa6e10x.dtsi:151 */
			clocks = < &pclkd 0x4 0x18 >;  /* in zephyr/dts/arm/renesas/ra/ra6/r7fa6e10x.dtsi:152 */
			reg = < 0x40169700 0x100 >;    /* in zephyr/dts/arm/renesas/ra/ra6/r7fa6e10x.dtsi:153 */
			#pwm-cells = < 0x3 >;          /* in zephyr/dts/arm/renesas/ra/ra6/r7fa6e10x.dtsi:154 */
			status = "disabled";           /* in zephyr/dts/arm/renesas/ra/ra6/r7fa6e10x.dtsi:155 */
		};

		/* node '/soc/trng' defined in zephyr/dts/arm/renesas/ra/ra6/r7fa6e10x.dtsi:158 */
		trng: trng {
			compatible = "renesas,ra-sce9-rng"; /* in zephyr/dts/arm/renesas/ra/ra6/r7fa6e10x.dtsi:159 */
			status = "okay";                    /* in zephyr/boards/renesas/fpb_ra6e1/fpb_ra6e1.dts:146 */
		};

		/* node '/soc/option-setting-ofs0@100a100' defined in zephyr/dts/arm/renesas/ra/ra6/r7fa6e10x.dtsi:163 */
		option_setting_ofs0: option-setting-ofs0@100a100 {
			compatible = "zephyr,memory-region";      /* in zephyr/dts/arm/renesas/ra/ra6/r7fa6e10x.dtsi:164 */
			zephyr,memory-region = "OFS_OFS0_MEMORY"; /* in zephyr/dts/arm/renesas/ra/ra6/r7fa6e10x.dtsi:165 */
			reg = < 0x100a100 0x4 >;                  /* in zephyr/dts/arm/renesas/ra/ra6/r7fa6e10x.dtsi:166 */
			status = "okay";                          /* in zephyr/dts/arm/renesas/ra/ra6/r7fa6e10x.dtsi:167 */
		};

		/* node '/soc/option-setting-dualsel@100a110' defined in zephyr/dts/arm/renesas/ra/ra6/r7fa6e10x.dtsi:170 */
		option_setting_dualsel: option-setting-dualsel@100a110 {
			compatible = "zephyr,memory-region";         /* in zephyr/dts/arm/renesas/ra/ra6/r7fa6e10x.dtsi:171 */
			zephyr,memory-region = "OFS_DUALSEL_MEMORY"; /* in zephyr/dts/arm/renesas/ra/ra6/r7fa6e10x.dtsi:172 */
			reg = < 0x100a110 0x4 >;                     /* in zephyr/dts/arm/renesas/ra/ra6/r7fa6e10x.dtsi:173 */
			status = "okay";                             /* in zephyr/dts/arm/renesas/ra/ra6/r7fa6e10x.dtsi:174 */
		};

		/* node '/soc/option-setting-ofs1-sec@100a200' defined in zephyr/dts/arm/renesas/ra/ra6/r7fa6e10x.dtsi:177 */
		option_setting_ofs1_sec: option-setting-ofs1-sec@100a200 {
			compatible = "zephyr,memory-region";          /* in zephyr/dts/arm/renesas/ra/ra6/r7fa6e10x.dtsi:178 */
			zephyr,memory-region = "OFS_OFS1_SEC_MEMORY"; /* in zephyr/dts/arm/renesas/ra/ra6/r7fa6e10x.dtsi:179 */
			reg = < 0x100a200 0x4 >;                      /* in zephyr/dts/arm/renesas/ra/ra6/r7fa6e10x.dtsi:180 */
			status = "okay";                              /* in zephyr/dts/arm/renesas/ra/ra6/r7fa6e10x.dtsi:181 */
		};

		/* node '/soc/option-setting-banksel-sec@100a210' defined in zephyr/dts/arm/renesas/ra/ra6/r7fa6e10x.dtsi:184 */
		option_setting_banksel_sec: option-setting-banksel-sec@100a210 {
			compatible = "zephyr,memory-region";             /* in zephyr/dts/arm/renesas/ra/ra6/r7fa6e10x.dtsi:185 */
			zephyr,memory-region = "OFS_BANKSEL_SEC_MEMORY"; /* in zephyr/dts/arm/renesas/ra/ra6/r7fa6e10x.dtsi:186 */
			reg = < 0x100a210 0x4 >;                         /* in zephyr/dts/arm/renesas/ra/ra6/r7fa6e10x.dtsi:187 */
			status = "okay";                                 /* in zephyr/dts/arm/renesas/ra/ra6/r7fa6e10x.dtsi:188 */
		};

		/* node '/soc/option-setting-bps-sec@100a240' defined in zephyr/dts/arm/renesas/ra/ra6/r7fa6e10x.dtsi:191 */
		option_setting_bps_sec: option-setting-bps-sec@100a240 {
			compatible = "zephyr,memory-region";         /* in zephyr/dts/arm/renesas/ra/ra6/r7fa6e10x.dtsi:192 */
			zephyr,memory-region = "OFS_BPS_SEC_MEMORY"; /* in zephyr/dts/arm/renesas/ra/ra6/r7fa6e10x.dtsi:193 */
			reg = < 0x100a240 0xc >;                     /* in zephyr/dts/arm/renesas/ra/ra6/r7fa6e10x.dtsi:194 */
			status = "okay";                             /* in zephyr/dts/arm/renesas/ra/ra6/r7fa6e10x.dtsi:195 */
		};

		/* node '/soc/option-setting-pbps-sec@100a260' defined in zephyr/dts/arm/renesas/ra/ra6/r7fa6e10x.dtsi:198 */
		option_setting_pbps_sec: option-setting-pbps-sec@100a260 {
			compatible = "zephyr,memory-region";          /* in zephyr/dts/arm/renesas/ra/ra6/r7fa6e10x.dtsi:199 */
			zephyr,memory-region = "OFS_PBPS_SEC_MEMORY"; /* in zephyr/dts/arm/renesas/ra/ra6/r7fa6e10x.dtsi:200 */
			reg = < 0x100a260 0xc >;                      /* in zephyr/dts/arm/renesas/ra/ra6/r7fa6e10x.dtsi:201 */
			status = "okay";                              /* in zephyr/dts/arm/renesas/ra/ra6/r7fa6e10x.dtsi:202 */
		};

		/* node '/soc/option-setting-ofs1-sel@100a280' defined in zephyr/dts/arm/renesas/ra/ra6/r7fa6e10x.dtsi:205 */
		option_setting_ofs1_sel: option-setting-ofs1-sel@100a280 {
			compatible = "zephyr,memory-region";          /* in zephyr/dts/arm/renesas/ra/ra6/r7fa6e10x.dtsi:206 */
			zephyr,memory-region = "OFS_OFS1_SEL_MEMORY"; /* in zephyr/dts/arm/renesas/ra/ra6/r7fa6e10x.dtsi:207 */
			reg = < 0x100a280 0x4 >;                      /* in zephyr/dts/arm/renesas/ra/ra6/r7fa6e10x.dtsi:208 */
			status = "okay";                              /* in zephyr/dts/arm/renesas/ra/ra6/r7fa6e10x.dtsi:209 */
		};

		/* node '/soc/option-setting-banksel-sel@100a290' defined in zephyr/dts/arm/renesas/ra/ra6/r7fa6e10x.dtsi:212 */
		option_setting_banksel_sel: option-setting-banksel-sel@100a290 {
			compatible = "zephyr,memory-region";             /* in zephyr/dts/arm/renesas/ra/ra6/r7fa6e10x.dtsi:213 */
			zephyr,memory-region = "OFS_BANKSEL_SEL_MEMORY"; /* in zephyr/dts/arm/renesas/ra/ra6/r7fa6e10x.dtsi:214 */
			reg = < 0x100a290 0x4 >;                         /* in zephyr/dts/arm/renesas/ra/ra6/r7fa6e10x.dtsi:215 */
			status = "okay";                                 /* in zephyr/dts/arm/renesas/ra/ra6/r7fa6e10x.dtsi:216 */
		};

		/* node '/soc/option-setting-bps-sel@100a2c0' defined in zephyr/dts/arm/renesas/ra/ra6/r7fa6e10x.dtsi:219 */
		option_setting_bps_sel: option-setting-bps-sel@100a2c0 {
			compatible = "zephyr,memory-region";         /* in zephyr/dts/arm/renesas/ra/ra6/r7fa6e10x.dtsi:220 */
			zephyr,memory-region = "OFS_BPS_SEL_MEMORY"; /* in zephyr/dts/arm/renesas/ra/ra6/r7fa6e10x.dtsi:221 */
			reg = < 0x100a2c0 0xc >;                     /* in zephyr/dts/arm/renesas/ra/ra6/r7fa6e10x.dtsi:222 */
			status = "okay";                             /* in zephyr/dts/arm/renesas/ra/ra6/r7fa6e10x.dtsi:223 */
		};
	};

	/* node '/cpus' defined in zephyr/dts/arm/renesas/ra/ra6/ra6-cm33-common.dtsi:15 */
	cpus {
		#address-cells = < 0x1 >; /* in zephyr/dts/arm/renesas/ra/ra6/ra6-cm33-common.dtsi:16 */
		#size-cells = < 0x0 >;    /* in zephyr/dts/arm/renesas/ra/ra6/ra6-cm33-common.dtsi:17 */

		/* node '/cpus/cpu@0' defined in zephyr/dts/arm/renesas/ra/ra6/ra6-cm33-common.dtsi:19 */
		cpu@0 {
			device_type = "cpu";           /* in zephyr/dts/arm/renesas/ra/ra6/ra6-cm33-common.dtsi:20 */
			compatible = "arm,cortex-m33"; /* in zephyr/dts/arm/renesas/ra/ra6/ra6-cm33-common.dtsi:21 */
			reg = < 0x0 >;                 /* in zephyr/dts/arm/renesas/ra/ra6/ra6-cm33-common.dtsi:22 */
			#address-cells = < 0x1 >;      /* in zephyr/dts/arm/renesas/ra/ra6/ra6-cm33-common.dtsi:23 */
			#size-cells = < 0x1 >;         /* in zephyr/dts/arm/renesas/ra/ra6/ra6-cm33-common.dtsi:24 */

			/* node '/cpus/cpu@0/mpu@e000ed90' defined in zephyr/dts/arm/renesas/ra/ra6/ra6-cm33-common.dtsi:26 */
			mpu: mpu@e000ed90 {
				compatible = "arm,armv8m-mpu"; /* in zephyr/dts/arm/renesas/ra/ra6/ra6-cm33-common.dtsi:27 */
				reg = < 0xe000ed90 0x40 >;     /* in zephyr/dts/arm/renesas/ra/ra6/ra6-cm33-common.dtsi:28 */
			};
		};
	};

	/* node '/usbfs-phy' defined in zephyr/dts/arm/renesas/ra/ra6/ra6-cm33-common.dtsi:596 */
	usbfs_phy: usbfs-phy {
		compatible = "usb-nop-xceiv"; /* in zephyr/dts/arm/renesas/ra/ra6/ra6-cm33-common.dtsi:597 */
		#phy-cells = < 0x0 >;         /* in zephyr/dts/arm/renesas/ra/ra6/ra6-cm33-common.dtsi:598 */
		phandle = < 0x1a >;           /* in zephyr/dts/arm/renesas/ra/ra6/ra6-cm33-common.dtsi:353 */
	};

	/* node '/clocks' defined in zephyr/dts/arm/renesas/ra/ra6/r7fa6e10x.dtsi:227 */
	clocks: clocks {
		#address-cells = < 0x1 >; /* in zephyr/dts/arm/renesas/ra/ra6/r7fa6e10x.dtsi:228 */
		#size-cells = < 0x1 >;    /* in zephyr/dts/arm/renesas/ra/ra6/r7fa6e10x.dtsi:229 */

		/* node '/clocks/clock-main-osc' defined in zephyr/dts/arm/renesas/ra/ra6/r7fa6e10x.dtsi:231 */
		xtal: clock-main-osc {
			compatible = "renesas,ra-cgc-external-clock"; /* in zephyr/dts/arm/renesas/ra/ra6/r7fa6e10x.dtsi:232 */
			clock-frequency = < 0x1312d00 >;              /* in zephyr/dts/arm/renesas/ra/ra6/r7fa6e10x.dtsi:233 */
			#clock-cells = < 0x0 >;                       /* in zephyr/dts/arm/renesas/ra/ra6/r7fa6e10x.dtsi:234 */
			status = "disabled";                          /* in zephyr/dts/arm/renesas/ra/ra6/r7fa6e10x.dtsi:235 */
		};

		/* node '/clocks/clock-hoco' defined in zephyr/dts/arm/renesas/ra/ra6/r7fa6e10x.dtsi:238 */
		hoco: clock-hoco {
			compatible = "fixed-clock";      /* in zephyr/dts/arm/renesas/ra/ra6/r7fa6e10x.dtsi:239 */
			clock-frequency = < 0x1312d00 >; /* in zephyr/dts/arm/renesas/ra/ra6/r7fa6e10x.dtsi:240 */
			#clock-cells = < 0x0 >;          /* in zephyr/dts/arm/renesas/ra/ra6/r7fa6e10x.dtsi:241 */
			phandle = < 0x1f >;              /* in zephyr/boards/renesas/fpb_ra6e1/fpb_ra6e1.dts:101 */
		};

		/* node '/clocks/clock-moco' defined in zephyr/dts/arm/renesas/ra/ra6/r7fa6e10x.dtsi:244 */
		moco: clock-moco {
			compatible = "fixed-clock";     /* in zephyr/dts/arm/renesas/ra/ra6/r7fa6e10x.dtsi:245 */
			clock-frequency = < 0x7a1200 >; /* in zephyr/dts/arm/renesas/ra/ra6/r7fa6e10x.dtsi:246 */
			#clock-cells = < 0x0 >;         /* in zephyr/dts/arm/renesas/ra/ra6/r7fa6e10x.dtsi:247 */
		};

		/* node '/clocks/clock-loco' defined in zephyr/dts/arm/renesas/ra/ra6/r7fa6e10x.dtsi:250 */
		loco: clock-loco {
			compatible = "fixed-clock";   /* in zephyr/dts/arm/renesas/ra/ra6/r7fa6e10x.dtsi:251 */
			clock-frequency = < 0x8000 >; /* in zephyr/dts/arm/renesas/ra/ra6/r7fa6e10x.dtsi:252 */
			#clock-cells = < 0x0 >;       /* in zephyr/dts/arm/renesas/ra/ra6/r7fa6e10x.dtsi:253 */
		};

		/* node '/clocks/clock-subclk' defined in zephyr/dts/arm/renesas/ra/ra6/r7fa6e10x.dtsi:256 */
		subclk: clock-subclk {
			compatible = "renesas,ra-cgc-subclk"; /* in zephyr/dts/arm/renesas/ra/ra6/r7fa6e10x.dtsi:257 */
			clock-frequency = < 0x8000 >;         /* in zephyr/dts/arm/renesas/ra/ra6/r7fa6e10x.dtsi:258 */
			#clock-cells = < 0x0 >;               /* in zephyr/dts/arm/renesas/ra/ra6/r7fa6e10x.dtsi:259 */
			status = "okay";                      /* in zephyr/boards/renesas/fpb_ra6e1/fpb_ra6e1.dts:97 */
		};

		/* node '/clocks/pll' defined in zephyr/dts/arm/renesas/ra/ra6/r7fa6e10x.dtsi:263 */
		pll: pll {
			compatible = "renesas,ra-cgc-pll"; /* in zephyr/dts/arm/renesas/ra/ra6/r7fa6e10x.dtsi:264 */
			#clock-cells = < 0x0 >;            /* in zephyr/dts/arm/renesas/ra/ra6/r7fa6e10x.dtsi:265 */
			clocks = < &hoco >;                /* in zephyr/boards/renesas/fpb_ra6e1/fpb_ra6e1.dts:101 */
			div = < 0x2 >;                     /* in zephyr/boards/renesas/fpb_ra6e1/fpb_ra6e1.dts:102 */
			mul = < 0x14 0x0 >;                /* in zephyr/boards/renesas/fpb_ra6e1/fpb_ra6e1.dts:103 */
			status = "okay";                   /* in zephyr/boards/renesas/fpb_ra6e1/fpb_ra6e1.dts:104 */
			phandle = < 0x20 >;                /* in zephyr/dts/arm/renesas/ra/ra6/r7fa6e10x.dtsi:291 */
		};

		/* node '/clocks/pll2' defined in zephyr/dts/arm/renesas/ra/ra6/r7fa6e10x.dtsi:274 */
		pll2: pll2 {
			compatible = "renesas,ra-cgc-pll"; /* in zephyr/dts/arm/renesas/ra/ra6/r7fa6e10x.dtsi:275 */
			#clock-cells = < 0x0 >;            /* in zephyr/dts/arm/renesas/ra/ra6/r7fa6e10x.dtsi:276 */
			div = < 0x2 >;                     /* in zephyr/dts/arm/renesas/ra/ra6/r7fa6e10x.dtsi:279 */
			mul = < 0x14 0x0 >;                /* in zephyr/dts/arm/renesas/ra/ra6/r7fa6e10x.dtsi:280 */
			status = "disabled";               /* in zephyr/dts/arm/renesas/ra/ra6/r7fa6e10x.dtsi:281 */
		};

		/* node '/clocks/pclkblock@40084000' defined in zephyr/dts/arm/renesas/ra/ra6/r7fa6e10x.dtsi:284 */
		pclkblock: pclkblock@40084000 {
			compatible = "renesas,ra-cgc-pclk-block"; /* in zephyr/dts/arm/renesas/ra/ra6/r7fa6e10x.dtsi:285 */
			reg = < 0x40084000 0x4 >,
			      < 0x40084004 0x4 >,
			      < 0x40084008 0x4 >,
			      < 0x4008400c 0x4 >,
			      < 0x40084010 0x4 >;                 /* in zephyr/dts/arm/renesas/ra/ra6/r7fa6e10x.dtsi:286 */
			reg-names = "MSTPA",
			            "MSTPB",
			            "MSTPC",
			            "MSTPD",
			            "MSTPE";                      /* in zephyr/dts/arm/renesas/ra/ra6/r7fa6e10x.dtsi:288 */
			#clock-cells = < 0x0 >;                   /* in zephyr/dts/arm/renesas/ra/ra6/r7fa6e10x.dtsi:290 */
			clocks = < &pll >;                        /* in zephyr/dts/arm/renesas/ra/ra6/r7fa6e10x.dtsi:291 */
			status = "okay";                          /* in zephyr/dts/arm/renesas/ra/ra6/r7fa6e10x.dtsi:292 */

			/* node '/clocks/pclkblock@40084000/iclk' defined in zephyr/dts/arm/renesas/ra/ra6/r7fa6e10x.dtsi:294 */
			iclk: iclk {
				compatible = "renesas,ra-cgc-pclk"; /* in zephyr/dts/arm/renesas/ra/ra6/r7fa6e10x.dtsi:295 */
				clock-frequency = < 0xbebc200 >;    /* in zephyr/dts/arm/renesas/ra/ra6/r7fa6e10x.dtsi:296 */
				div = < 0x1 >;                      /* in zephyr/dts/arm/renesas/ra/ra6/r7fa6e10x.dtsi:297 */
				#clock-cells = < 0x2 >;             /* in zephyr/dts/arm/renesas/ra/ra6/r7fa6e10x.dtsi:298 */
				status = "okay";                    /* in zephyr/dts/arm/renesas/ra/ra6/r7fa6e10x.dtsi:299 */
				phandle = < 0x13 >;                 /* in zephyr/dts/arm/renesas/ra/ra6/ra6-cm33-common.dtsi:115 */
			};

			/* node '/clocks/pclkblock@40084000/pclka' defined in zephyr/dts/arm/renesas/ra/ra6/r7fa6e10x.dtsi:302 */
			pclka: pclka {
				compatible = "renesas,ra-cgc-pclk"; /* in zephyr/dts/arm/renesas/ra/ra6/r7fa6e10x.dtsi:303 */
				div = < 0x2 >;                      /* in zephyr/dts/arm/renesas/ra/ra6/r7fa6e10x.dtsi:304 */
				#clock-cells = < 0x2 >;             /* in zephyr/dts/arm/renesas/ra/ra6/r7fa6e10x.dtsi:305 */
				status = "okay";                    /* in zephyr/dts/arm/renesas/ra/ra6/r7fa6e10x.dtsi:306 */
				phandle = < 0x14 >;                 /* in zephyr/dts/arm/renesas/ra/ra6/ra6-cm33-common.dtsi:132 */
			};

			/* node '/clocks/pclkblock@40084000/pclkb' defined in zephyr/dts/arm/renesas/ra/ra6/r7fa6e10x.dtsi:309 */
			pclkb: pclkb {
				compatible = "renesas,ra-cgc-pclk"; /* in zephyr/dts/arm/renesas/ra/ra6/r7fa6e10x.dtsi:310 */
				div = < 0x4 >;                      /* in zephyr/dts/arm/renesas/ra/ra6/r7fa6e10x.dtsi:311 */
				#clock-cells = < 0x2 >;             /* in zephyr/dts/arm/renesas/ra/ra6/r7fa6e10x.dtsi:312 */
				status = "okay";                    /* in zephyr/dts/arm/renesas/ra/ra6/r7fa6e10x.dtsi:313 */
				phandle = < 0x2 >;                  /* in zephyr/dts/arm/renesas/ra/ra6/ra6-cm33-common.dtsi:46 */
			};

			/* node '/clocks/pclkblock@40084000/pclkc' defined in zephyr/dts/arm/renesas/ra/ra6/r7fa6e10x.dtsi:316 */
			pclkc: pclkc {
				compatible = "renesas,ra-cgc-pclk"; /* in zephyr/dts/arm/renesas/ra/ra6/r7fa6e10x.dtsi:317 */
				div = < 0x4 >;                      /* in zephyr/dts/arm/renesas/ra/ra6/r7fa6e10x.dtsi:318 */
				#clock-cells = < 0x2 >;             /* in zephyr/dts/arm/renesas/ra/ra6/r7fa6e10x.dtsi:319 */
				status = "okay";                    /* in zephyr/dts/arm/renesas/ra/ra6/r7fa6e10x.dtsi:320 */
			};

			/* node '/clocks/pclkblock@40084000/pclkd' defined in zephyr/dts/arm/renesas/ra/ra6/r7fa6e10x.dtsi:323 */
			pclkd: pclkd {
				compatible = "renesas,ra-cgc-pclk"; /* in zephyr/dts/arm/renesas/ra/ra6/r7fa6e10x.dtsi:324 */
				div = < 0x2 >;                      /* in zephyr/dts/arm/renesas/ra/ra6/r7fa6e10x.dtsi:325 */
				#clock-cells = < 0x2 >;             /* in zephyr/dts/arm/renesas/ra/ra6/r7fa6e10x.dtsi:326 */
				status = "okay";                    /* in zephyr/dts/arm/renesas/ra/ra6/r7fa6e10x.dtsi:327 */
				phandle = < 0x1d >;                 /* in zephyr/dts/arm/renesas/ra/ra6/ra6-cm33-common.dtsi:520 */
			};

			/* node '/clocks/pclkblock@40084000/fclk' defined in zephyr/dts/arm/renesas/ra/ra6/r7fa6e10x.dtsi:330 */
			fclk: fclk {
				compatible = "renesas,ra-cgc-pclk"; /* in zephyr/dts/arm/renesas/ra/ra6/r7fa6e10x.dtsi:331 */
				div = < 0x4 >;                      /* in zephyr/dts/arm/renesas/ra/ra6/r7fa6e10x.dtsi:332 */
				#clock-cells = < 0x2 >;             /* in zephyr/dts/arm/renesas/ra/ra6/r7fa6e10x.dtsi:333 */
				status = "okay";                    /* in zephyr/dts/arm/renesas/ra/ra6/r7fa6e10x.dtsi:334 */
			};

			/* node '/clocks/pclkblock@40084000/uclk' defined in zephyr/dts/arm/renesas/ra/ra6/r7fa6e10x.dtsi:337 */
			uclk: uclk {
				compatible = "renesas,ra-cgc-pclk"; /* in zephyr/dts/arm/renesas/ra/ra6/r7fa6e10x.dtsi:338 */
				#clock-cells = < 0x2 >;             /* in zephyr/dts/arm/renesas/ra/ra6/r7fa6e10x.dtsi:339 */
				status = "disabled";                /* in zephyr/dts/arm/renesas/ra/ra6/r7fa6e10x.dtsi:340 */
				phandle = < 0x1b >;                 /* in zephyr/dts/arm/renesas/ra/ra6/ra6-cm33-common.dtsi:354 */
			};

			/* node '/clocks/pclkblock@40084000/clkout' defined in zephyr/dts/arm/renesas/ra/ra6/r7fa6e10x.dtsi:343 */
			clkout: clkout {
				compatible = "renesas,ra-cgc-pclk"; /* in zephyr/dts/arm/renesas/ra/ra6/r7fa6e10x.dtsi:344 */
				#clock-cells = < 0x2 >;             /* in zephyr/dts/arm/renesas/ra/ra6/r7fa6e10x.dtsi:345 */
				status = "disabled";                /* in zephyr/dts/arm/renesas/ra/ra6/r7fa6e10x.dtsi:346 */
			};
		};
	};

	/* node '/leds' defined in zephyr/boards/renesas/fpb_ra6e1/fpb_ra6e1.dts:29 */
	leds {
		compatible = "gpio-leds"; /* in zephyr/boards/renesas/fpb_ra6e1/fpb_ra6e1.dts:30 */

		/* node '/leds/led1' defined in zephyr/boards/renesas/fpb_ra6e1/fpb_ra6e1.dts:32 */
		led1: led1 {
			gpios = < &ioport4 0x7 0x0 >; /* in zephyr/boards/renesas/fpb_ra6e1/fpb_ra6e1.dts:33 */
			label = "LED1";               /* in zephyr/boards/renesas/fpb_ra6e1/fpb_ra6e1.dts:34 */
		};

		/* node '/leds/led2' defined in zephyr/boards/renesas/fpb_ra6e1/fpb_ra6e1.dts:37 */
		led2: led2 {
			gpios = < &ioport4 0x8 0x0 >; /* in zephyr/boards/renesas/fpb_ra6e1/fpb_ra6e1.dts:38 */
			label = "LED2";               /* in zephyr/boards/renesas/fpb_ra6e1/fpb_ra6e1.dts:39 */
		};
	};

	/* node '/buttons' defined in zephyr/boards/renesas/fpb_ra6e1/fpb_ra6e1.dts:43 */
	buttons {
		compatible = "gpio-keys"; /* in zephyr/boards/renesas/fpb_ra6e1/fpb_ra6e1.dts:44 */

		/* node '/buttons/s1' defined in zephyr/boards/renesas/fpb_ra6e1/fpb_ra6e1.dts:46 */
		button0: s1 {
			gpios = < &ioport2 0x5 0x11 >;  /* in zephyr/boards/renesas/fpb_ra6e1/fpb_ra6e1.dts:47 */
			label = "Push button switch 1"; /* in zephyr/boards/renesas/fpb_ra6e1/fpb_ra6e1.dts:48 */
			zephyr,code = < 0xb >;          /* in zephyr/boards/renesas/fpb_ra6e1/fpb_ra6e1.dts:49 */
		};
	};
};
